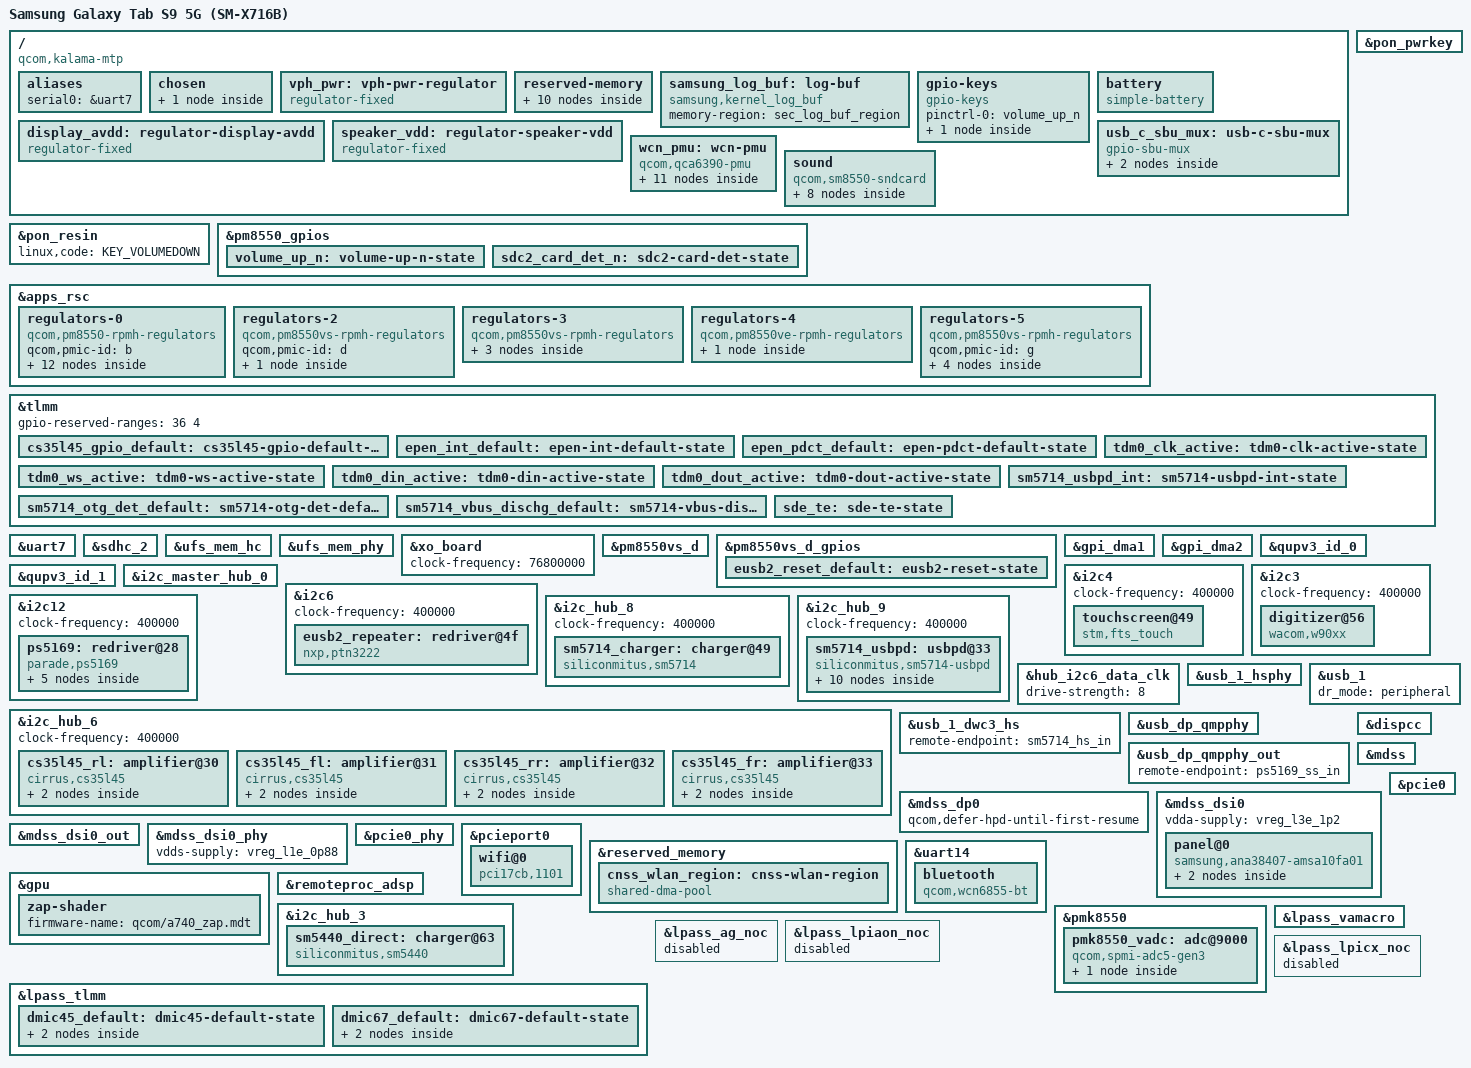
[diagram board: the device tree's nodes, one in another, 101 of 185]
// SPDX-License-Identifier: GPL-2.0-only OR BSD-3-Clause
/*
 * Minimal bring-up devicetree for the Samsung Galaxy Tab S9 5G (SM-X716B).
 *
 * Display (DSI panel) and USB were confirmed working on real hardware in
 * Session 5. Touchscreen (Session 6/7) works end to end on real hardware:
 * chip ID validated, resident firmware read back, correct coordinates.
 * Getting there took three real bugs (a wrong AVDD voltage not achievable
 * on that LDO's hardware ladder, CONFIG_QCOM_GPI_DMA shipping as a module
 * with no modprobe available, and a coordinate range copied from the wrong
 * stock board revision), each root-caused from source rather than guessed
 * -- see docs/porting-log.md's Session 7 entry for the full investigation.
 *
 * Structural template: arch/arm64/boot/dts/qcom/sm8550-samsung-q5q.dts
 * (mainline, Samsung Galaxy Z Fold5 -- a real accepted-upstream SM8550
 * Samsung board, not just the out-of-tree X910 Ultra reference). Board
 * facts (reserved-memory carveouts, msm-id/board-id, UFS regulator rail
 * indices, console UART) cross-checked against Samsung's stock downstream
 * source for THIS device family at
 * android_kernel_samsung_gts9/.../galaxytab/gts9/gts9_eur_openx_w00_r00.dts
 * -- see docs/hardware-facts.md for exactly which facts are measured vs.
 * inherited vs. assumed, and why.
 *
 * Deliberately minimal for the Phase 1-3 bring-up MVP: only what's needed
 * to reach a shell over a rootfs, now extended with a working DSI panel
 * (AMSA10FA01, from-scratch driver -- see kernel/drivers/panel-samsung-
 * ana38407-x716.c) and touchscreen (fts1ba90a, from-scratch driver -- see
 * kernel/drivers/touchscreen-fts1ba90a-x716.c). Still explicitly NOT wired
 * up (see docs/hardware-facts.md non-goals): cameras, WCN7850 WiFi/BT,
 * audio, sensors, cellular modem (permanent non-goal), USB-PD beyond
 * whatever sm8550.dtsi/pm8550*.dtsi already enable by default.
 */

/dts-v1/;

#include <dt-bindings/pinctrl/qcom,pmic-gpio.h>
#include <dt-bindings/regulator/qcom,rpmh-regulator.h>
#include <dt-bindings/usb/pd.h>
#include "sm8550.dtsi"
#include "pm8550.dtsi"
#include "pm8550vs.dtsi"
#include "pmk8550.dtsi"

/*
 * Samsung's ADSP/SLPI firmware needs a larger carveout than the SM8550
 * reference value -- copied verbatim from gts9wifi-fedora's own real,
 * hardware-derived DTS (their own comment: "Samsung's ADSP/SLPI carveout
 * is larger than the SM8550 reference value"). Same Samsung ADSP firmware
 * build/reference platform across the WiFi and 5G SKUs of this same
 * "gts9" tablet family (matches every other ADSP/AOP/regulator fact this
 * project has cross-checked between the two boards this session, all
 * identical) -- not yet independently re-measured against X716B's own
 * stock DTS, flagged here rather than silently assumed. Must delete the
 * default node from sm8550.dtsi first (its own reg/size can't be
 * redefined in place) before declaring the resized one under the same
 * label inside the reserved-memory block below.
 */
/delete-node/ &adspslpi_mem;

/*
 * sm8550.dtsi's remoteproc_mpss/remoteproc_adsp/remoteproc_cdsp nodes all
 * default to status = "disabled" (confirmed by reading sm8550.dtsi
 * directly) unless a board opts in with firmware-name + status="okay", as
 * sm8550-samsung-q5q.dts does. Cellular (remoteproc_mpss) and CDSP stay
 * non-goals (see docs/hardware-facts.md) -- their default
 * mpss_mem/mpss_dsm_mem/rmtfs_mem/cdsp_mem reserved-memory regions are
 * left completely untouched: harmless reserved space, no dangling
 * phandle references, no remoteproc firmware load attempts. (An earlier
 * draft of this file tried to /delete-node/ those regions to "avoid
 * declaring unused remoteproc nodes" -- that was wrong: the nodes stay in
 * the tree regardless of status, and deleting only the memory-region
 * without also either deleting or redefining it under the same label
 * breaks the phandle reference. Leaving both alone is simpler and
 * correct.)
 *
 * ADSP (remoteproc_adsp) is now enabled (gts9wifi-fedora pivot, Session
 * 9+ -- needed for sensors/SSC, see docs/porting-log.md), so its own
 * adspslpi_mem carveout below is NOT left at the mainline default --
 * confirmed against gts9wifi-fedora's real, hardware-derived DTS that
 * Samsung's ADSP/SLPI firmware needs a larger carveout than the SM8550
 * reference value.
 */

/ {
	model = "Samsung Galaxy Tab S9 5G (SM-X716B)";

	/*
	 * qcom,msm-id / qcom,board-id below are copied verbatim from Samsung's
	 * currently-shipping stock DTS for this device (measured -- see
	 * hardware-facts.md), on the theory that keeping values ABL is known to
	 * already accept for THIS device is the safer first attempt than
	 * omitting them. NOTE: sm8550-samsung-q5q.dts (mainline, Z Fold5) uses
	 * a plain two-string compatible with no qcom,msm-id/board-id at all,
	 * and presumably still boots via the same family of Samsung ABL -- if
	 * this DTS is rejected by X716's ABL, try dropping the
	 * qcom,kalama-mtp/qcom,mtp/msm-id/board-id properties entirely as a
	 * second attempt before assuming a deeper problem. Track whichever
	 * turns out to be true in docs/hardware-facts.md.
	 */
	compatible = "qcom,kalama-mtp", "qcom,kalama", "qcom,mtp",
		     "samsung,gts9-5g", "qcom,sm8550";
	chassis-type = "tablet";

	qcom,msm-id = <0x207 0x10000 0x218 0x10000 0x207 0x20000 0x218 0x20000>;
	qcom,board-id = <0x10008 0x04>; /* board-id,04 -- was board-id,00 (r00), changed
					  * 2026-09-07 after adopting gts9wifi-fedora (a real,
					  * mature mainline port for the Wi-Fi-only sibling
					  * tablet) as a reference: this tablet reports
					  * board-id,04 live via /proc/device-tree/model on
					  * stock Android (already noted below, previously
					  * untested), matching r04
					  * (gts9_eur_openx_w00_r04.dts, the same stock DTS
					  * revision this board's touchscreen node below is
					  * already sourced from). See docs/porting-log.md's
					  * gts9wifi-fedora pivot entry. */

	aliases {
		serial0 = &uart7; /* measured: same MMIO address (0xa9c000) as X716
				   * downstream's qup_hsuart@a9c000/hsuart5, and matches
				   * sm8550-samsung-q5q.dts's own console assignment. */
	};

	chosen {
		#address-cells = <2>;
		#size-cells = <2>;
		ranges;

		/*
		 * No real AMSA10FA01 panel driver exists yet, but this doesn't
		 * need one: ABL already configures a live scanout buffer for its
		 * own boot splash/log-drawing calls (confirmed repeatedly in this
		 * device's own ABL logs -- "GlibDrawJpegImage"/"GlibDrawBootImage",
		 * "GlibGetLCDResolution: [MAIN] Display W=2560, H=1600") --
		 * "simple-framebuffer" just inherits that already-running scanout
		 * for a plain fbcon text console, no real display driver needed.
		 * Added 2026-09-05 to get a directly-visible signal (kernel/init
		 * console text on the panel) after the sec-log/last_kmsg
		 * diagnostic channel proved unable to survive the necessary
		 * boot-cycle-to-reach-TWRP transition for late-boot/userspace
		 * events (see docs/porting-log.md).
		 *
		 * Address/size (0xb8000000, 0x2b00000) and format (a8r8g8b8) are
		 * copied from sm8550-samsung-q5q.dts (mainline, Z Fold5 -- same
		 * SoC generation) UNVERIFIED for this board specifically -- only
		 * width/height (2560x1600) are actually measured for X716 (from
		 * its own ABL log). If the panel shows garbage/noise instead of
		 * text, the address or format (not the resolution) is the first
		 * thing to revisit.
		 */
		framebuffer: framebuffer@b8000000 {
			compatible = "simple-framebuffer";
			reg = <0x0 0xb8000000 0x0 0x2b00000>;
			width = <2560>;
			height = <1600>;
			stride = <(2560 * 4)>;
			format = "a8r8g8b8";
		};
	};

	vph_pwr: vph-pwr-regulator {
		compatible = "regulator-fixed";
		regulator-name = "vph_pwr";
		regulator-min-microvolt = <3700000>;
		regulator-max-microvolt = <3700000>;
		regulator-always-on;
		regulator-boot-on;
	};

	reserved-memory {
		/* Resized per the /delete-node/ comment above this file's includes. */
		adspslpi_mem: adspslpi@9ea00000 {
			reg = <0x0 0x9ea00000 0x0 0x59b4000>;
			no-map;
		};

		/*
		 * Samsung's own debug/log carveout cluster, copied verbatim
		 * (measured) from the X716 downstream DTS's fragment@103. All in a
		 * distinct high-memory DRAM region (0x8_80100000-0x8_8cd00000) far
		 * outside anything sm8550.dtsi reserves (all sub-4GB) -- no
		 * conflict. sec_log_buf_region is the primary Phase 2 console-less
		 * debug channel (see docs/boot-strategy.md, once written): TWRP is
		 * a known consumer of this exact region for /proc/last_kmsg-style
		 * readback after a hang. Reserving the whole cluster (not just
		 * sec_log) matters even though this port only actively uses one
		 * region -- touching memory TrustZone/secure firmware still
		 * expects reserved for the others risks a fatal NoC abort.
		 */
		sec_debug_region_pool: sec-debug-region-pool@880100000 {
			compatible = "samsung,carve-out";
			reg = <0x08 0x80100000 0x00 0xff000>;
		};

		sec_rst_ex_info_region: sec-rst-ex-info-region@8801ff000 {
			compatible = "samsung,carve-out";
			no-map;
			reg = <0x08 0x801ff000 0x00 0x1000>;
		};

		sec_log_buf_region: sec-log-buf-region@880200000 {
			compatible = "samsung,carve-out";
			reg = <0x08 0x80200000 0x00 0x200000>;
		};

		sec_debug_bl_region: sec-debug-bl-region@880400000 {
			compatible = "samsung,carve-out";
			no-map;
			reg = <0x08 0x80400000 0x00 0x500000>;
		};

		sec_pmsg_region: sec-pmsg-region@880900000 {
			compatible = "samsung,carve-out";
			reg = <0x08 0x80900000 0x00 0x200000>;
		};

		google_debug_kinfo_region: google-debug-kinfo-region@880b00000 {
			compatible = "samsung,carve-out";
			no-map;
			reg = <0x08 0x80b00000 0x00 0x1000>;
		};

		hdm_region: hdm-region@880b01000 {
			compatible = "removed-dma-pool";
			no-map;
			reg = <0x08 0x80b01000 0x00 0x1000>;
		};

		sec_qcom_rdx_bootdev_region: sec-qcom-rdx-bootdev-region@880c00000 {
			compatible = "samsung,carve-out";
			reg = <0x08 0x80c00000 0x00 0xad00000>;
		};

		/*
		 * Must be named exactly "splash-region" -- sm8550-samsung-q5q.dts
		 * carries the same node with the comment "The bootloader will only
		 * keep display hardware enabled if this memory region is named
		 * exactly 'splash_region'" (i.e. ABL itself checks the DTB it
		 * hands off to for this specific reserved-memory node before
		 * deciding whether to leave the display scanout live for Linux to
		 * inherit -- not just a Linux-side convention). Matches the
		 * framebuffer node's address/size above exactly; no-map so the
		 * kernel's normal allocator can't reuse this RAM before simplefb
		 * claims it.
		 */
		splash_region: splash-region@b8000000 {
			reg = <0x0 0xb8000000 0x0 0x2b00000>;
			no-map;
		};
	};

	/*
	 * Consumer of sec_log_buf_region above -- matched by
	 * kernel/drivers/samsung-x716-sec-log.c (a from-scratch reimplementation
	 * of Samsung's on-disk sec_log_buf format, not their driver code; see
	 * that file's header comment). Deliberately a plain node referencing
	 * the carveout via memory-region, matching how Samsung's own downstream
	 * driver is wired (a separate consumer node, not the reserved-memory
	 * node itself) -- confirmed by reading
	 * drivers/samsung/debug/log_buf/sec_log_buf_main.c in the X716
	 * downstream source, which matches on this same compatible string.
	 */
	samsung_log_buf: log-buf {
		compatible = "samsung,kernel_log_buf";
		memory-region = <&sec_log_buf_region>;
	};

	/*
	 * A `gpio-leds` "heartbeat" node on GPIO 18 (the vibration motor)
	 * lived here 2026-09-05 through 2026-09-08 as a "kernel is alive"
	 * bring-up signal, back before display/USB-serial/SSH gave any other
	 * way to see boot progress -- see docs/porting-log.md's Session 4/5
	 * entries for the full story. Removed once those real channels made
	 * it unnecessary: it had no purpose left except buzzing the tablet's
	 * motor for as long as the kernel ran, on every boot.
	 */

	/*
	 * Volume Up: the only one of the three physical buttons that's a real
	 * discrete GPIO rather than a PMIC PON-block pin (see &pon_pwrkey/
	 * &pon_resin below for Power/Volume Down). Confirmed identical across
	 * all three independent sources checked (gts9wifi-fedora's own X710,
	 * ubuntu-galaxy-tab-s9ultra's X910, and this exact device's own stock
	 * downstream DTS under android_kernel_samsung_gts9/ -- all four stock
	 * board-revision DTBs agree byte-for-byte): PM8550 (not PMK8550, not
	 * TLMM) GPIO6, active-low with an internal pull-up, 15 ms debounce.
	 * Pinctrl state for that pin is under &pm8550_gpios below.
	 */
	gpio-keys {
		compatible = "gpio-keys";
		pinctrl-names = "default";
		pinctrl-0 = <&volume_up_n>;

		key-volume-up {
			label = "Volume Up";
			linux,code = <KEY_VOLUMEUP>;
			gpios = <&pm8550_gpios 6 GPIO_ACTIVE_LOW>;
			debounce-interval = <15>;
			linux,can-disable;
			wakeup-source;
		};
	};
};

/*
 * Power and Volume Down: both are pins on the PMK8550 PMIC's own PON
 * (power-on) hardware block, not discrete GPIOs -- pmk8550.dtsi already
 * defines both `pon_pwrkey`/`pon_resin` (status "disabled", pwrkey
 * hardcoding linux,code = KEY_POWER, resin with no code of its own since
 * upstream leaves what it's wired to board-specific). Volume Down reuses
 * the PON block's RESIN ("reset-in") pin -- normally the hardware
 * power+resin force-reset combo -- as a plain key input instead, the same
 * reference-design pattern this whole SM8550 tablet family uses. Same
 * three-way confirmation as the gpio-keys node above.
 */
&pon_pwrkey {
	status = "okay";
};

&pon_resin {
	linux,code = <KEY_VOLUMEDOWN>;
	status = "okay";
};

&pm8550_gpios {
	volume_up_n: volume-up-n-state {
		pins = "gpio6";
		function = "normal";
		power-source = <1>; /* 1.8 V */
		bias-pull-up;
		input-enable;
	};
};

/*
 * RPMh regulators. Unlike sm8550.dtsi's other subsystems, individual
 * vreg_* rails are NOT provided by pm8550*.dtsi -- they must be
 * instantiated per-board as children of &apps_rsc, one regulators-N block
 * per physical PMIC die (letter = qcom,pmic-id), matching
 * sm8550-samsung-q5q.dts's structure exactly (confirmed by reading it in
 * full). Only the four rails this minimal board actually references are
 * defined here, not the full ~25-rail set a real board normally would --
 * add more as later phases wire up more hardware.
 *
 * vreg_l17b_2p5 (die b, UFS vcc) and vreg_l1g_1p2 (die g, UFS vccq) are
 * high-confidence: index+die letter cross-validated against X716
 * downstream's own pm_humu_l17/pm_v6g_l1 labels (the "g" in "v6g" matches
 * mainline's "g" die letter directly) and sm8550-samsung-q5q.dts.
 * vreg_l1d_0p88/vreg_l3e_1p2 (UFS PHY supplies) are LOWER confidence --
 * inherited from sm8550-samsung-q5q.dts only, not independently
 * cross-checked against X716 downstream (its ufs_mem_phy fragment uses
 * unresolved phandle placeholders in this decompiled DTS, so the die
 * letter/index couldn't be read directly). If UFS PHY init fails during
 * Phase 3 bring-up, re-verify these two first.
 */
&apps_rsc {
	regulators-0 {
		compatible = "qcom,pm8550-rpmh-regulators";
		qcom,pmic-id = "b";

		vreg_l17b_2p5: ldo17 {
			regulator-name = "vreg_l17b_2p5";
			regulator-min-microvolt = <2504000>;
			regulator-max-microvolt = <2504000>;
			regulator-initial-mode = <RPMH_REGULATOR_MODE_HPM>;
		};

		/*
		 * microSD card power rails. Tried 2026-09-05 (Session 4) for
		 * persistent SD-card-based logging, then reverted the same
		 * session out of caution to bisect an unrelated regression --
		 * that bisection (docs/porting-log.md's Session 4 entry)
		 * actually *exonerated* these rails (reverting reproduced the
		 * identical symptom), so they were never proven guilty of
		 * anything, just left out pending re-verification. Re-added
		 * in the Storage bring-up session, copied exactly from the
		 * sibling X910 Ultra port's own real-hardware-proven,
		 * daily-driver config
		 * (ubuntu-galaxy-tab-s9ultra/kernel/dts/sm8550-samsung-
		 * gts9uwifi.dts:515-527) -- note both use a real min/max
		 * *range* rather than an exact value, so neither risks the
		 * apply_uV/hardware-ladder mismatch that broke the
		 * touchscreen's AVDD rail (see docs/porting-log.md's Session
		 * 6/7 entries).
		 */
		vreg_l8b_1p8: ldo8 {
			regulator-name = "vreg_l8b_1p8";
			regulator-min-microvolt = <1800000>;
			regulator-max-microvolt = <3000000>;
			regulator-initial-mode = <RPMH_REGULATOR_MODE_HPM>;
		};

		vreg_l9b_2p9: ldo9 {
			regulator-name = "vreg_l9b_2p9";
			regulator-min-microvolt = <2960000>;
			regulator-max-microvolt = <3000000>;
			regulator-initial-mode = <RPMH_REGULATOR_MODE_HPM>;
		};

		/*
		 * Digital microphone bias (gts9wifi-fedora pivot). Their real DTS
		 * wires the VA macro's va-vdd-micb to this LDO (their pm_humu_l10,
		 * resource ldob10) at 1.8V; without it the driver falls back to a
		 * dummy regulator and the DMICs stay unpowered, so capture returns
		 * silence. Referenced by &lpass_vamacro's vdd-micb-supply below.
		 */
		vreg_l10b_1p8: ldo10 {
			regulator-name = "vreg_l10b_1p8";
			regulator-min-microvolt = <1800000>;
			regulator-max-microvolt = <1800000>;
			regulator-initial-mode = <RPMH_REGULATOR_MODE_HPM>;
			/*
			 * The VA macro declares vdd-micb as a DAPM regulator supply
			 * but never puts it in a route, so the widget is never
			 * powered and the rail stays off even with a capture
			 * running -- the microphones then sit unpowered and return
			 * digital silence. Until the driver wires that supply into
			 * the DMIC paths, keep the rail up.
			 */
			regulator-always-on;
		};

		/*
		 * NXP PTN3222 eUSB2 repeater rails (3.104V/1.8V). Copied from
		 * ubuntu-galaxy-tab-s9ultra by analogy, same confidence caveat as
		 * the rest of this session's USB additions -- see
		 * docs/porting-log.md's "Session 4" entry.
		 */
		vreg_l5b_3p104: ldo5 {
			regulator-name = "vreg_l5b_3p104";
			regulator-min-microvolt = <3104000>;
			regulator-max-microvolt = <3104000>;
			regulator-initial-mode = <RPMH_REGULATOR_MODE_HPM>;
			regulator-allow-set-load;
			regulator-allowed-modes = <RPMH_REGULATOR_MODE_LPM
						   RPMH_REGULATOR_MODE_HPM>;
		};

		vreg_l15b_1p8: ldo15 {
			regulator-name = "vreg_l15b_1p8";
			regulator-min-microvolt = <1800000>;
			regulator-max-microvolt = <1800000>;
			regulator-initial-mode = <RPMH_REGULATOR_MODE_HPM>;
			regulator-allow-set-load;
			regulator-allowed-modes = <RPMH_REGULATOR_MODE_LPM
						   RPMH_REGULATOR_MODE_HPM>;
		};

		/*
		 * ANA38407 panel rails (vddio/vdd/vci). Index letters/numbers
		 * (l11b/l12b/l13b) copied from ubuntu-galaxy-tab-s9ultra's own
		 * panel regulators by analogy -- same SoC generation, same
		 * reference-design die assignment pattern the UFS/USB rails
		 * on this board already independently confirm (see comments
		 * above &apps_rsc). UNVERIFIED for X716 specifically, unlike
		 * the voltages themselves: vddio (1.8V) and vci (3.0V) match
		 * the Ultra port exactly, but vdd here is 1.2V (not the
		 * Ultra's 1.1V) because X716's own stock downstream DTS
		 * decodes its dsi_panel_pwr_supply "vdd" entry as exactly
		 * 0x124f80 = 1,200,000 uV (see
		 * android_kernel_samsung_gts9/.../gts9_eur_openx_w00_r00.dts:9210-9219)
		 * -- a real, board-specific measurement, just not one that
		 * also tells us the LDO index it's wired to. If the panel
		 * never powers on, re-verify these three rails' index letters
		 * first (see docs/porting-log.md's Session 5 entry).
		 */
		vreg_l12b_1p8: ldo12 {
			regulator-name = "vreg_l12b_1p8";
			regulator-min-microvolt = <1800000>;
			regulator-max-microvolt = <1800000>;
			regulator-initial-mode = <RPMH_REGULATOR_MODE_HPM>;
		};

		vreg_l11b_1p2: ldo11 {
			regulator-name = "vreg_l11b_1p2";
			regulator-min-microvolt = <1200000>;
			regulator-max-microvolt = <1200000>;
			regulator-initial-mode = <RPMH_REGULATOR_MODE_HPM>;
		};

		vreg_l13b_3p0: ldo13 {
			regulator-name = "vreg_l13b_3p0";
			regulator-min-microvolt = <3000000>;
			regulator-max-microvolt = <3000000>;
			regulator-initial-mode = <RPMH_REGULATOR_MODE_HPM>;
		};

		/*
		 * Touch AVDD. Session 6 first defined this at 3300000 uV
		 * (`vreg_l14b_3p3`) -- reading the stock DTS's `tsp_avdd_ldo`
		 * as "3.3V" -- and that alone (regardless of whether anything
		 * ever called regulator_enable() on it) caused a real-hardware
		 * silent hard reset, reproducing identically whether the
		 * touchscreen's own i2c4 bus was enabled or disabled. The
		 * initial theory (a TrustZone-restricted PMIC resource, by
		 * analogy to this project's earlier reserved-GPIO-range crash)
		 * turned out to be wrong. Four parallel research agents
		 * (kernel-source tracing, the X910 Ultra sibling port, the
		 * downstream driver, and public docs/other SM8550 boards)
		 * converged on the real cause: 3300000 uV is not a value this
		 * LDO's hardware can produce at all. PM8550-b LDO14 is a
		 * pmic5_pldo, whose voltage ladder is 1504000 + N*8000 uV
		 * (N=0..255) -- (3300000-1504000)/8000 = 224.5, landing exactly
		 * between selector 224 (3296000) and 225 (3304000). Because
		 * regulator-min-microvolt == regulator-max-microvolt sets
		 * apply_uV (drivers/regulator/of_regulator.c), this gets
		 * checked unconditionally at PMIC registration time
		 * (machine_constraints_voltage(), drivers/regulator/core.c),
		 * which clamps to the achievable range (max_uV=3296000 <
		 * min_uV=3304000) and fails with -EINVAL *before* any RPMH
		 * command is ever sent for this rail. Because ldo14 was the
		 * last child node in this regulators-0 block, that single
		 * probe failure aborted rpmh_regulator_probe()'s child loop,
		 * and the resulting devm_regulator_register() teardown
		 * (device_unbind_cleanup() -> devres_release_all()) unregisters
		 * every *already-registered* sibling regulator from the same
		 * failed probe call too -- including vreg_l17b_2p5 (UFS vcc),
		 * which is why the whole board went dark rather than just
		 * touch failing to probe. cmd-db/TrustZone-restriction was an
		 * available theory but is actively refuted by the driver's own
		 * source: a cmd-db miss or unauthorized resource fails
		 * gracefully (dev_err + -ENODEV), never silently.
		 *
		 * 3200000 uV (an exact selector, N=212) is the correct value:
		 * it's what Qualcomm's own reference tree names this exact
		 * rail (kalama-regulators.dtsi's pm_humu_l14/L14B, which our
		 * board's stock DTS inherits unmodified -- its overlay only
		 * fixes up consumers, never redefines the regulator itself,
		 * confirmed by decompiling gts9_eur_openx_w00_r04.dts and
		 * finding no `&L14B { ... }` override anywhere in this
		 * device's tree), it's the exact value the sibling X910 Ultra
		 * port uses for the same physical LDO14 index powering its own
		 * touch chip's AVDD (`vreg_l14b_3p2`,
		 * ubuntu-galaxy-tab-s9ultra/kernel/dts/sm8550-samsung-
		 * gts9uwifi.dts), and it's the exact value mainline's own
		 * upstream Samsung SM8550 board uses for this same node
		 * (`vreg_l14b_3p2`, arch/arm64/boot/dts/qcom/sm8550-samsung-
		 * q5q.dts, the Galaxy Z Fold5 -- defined with zero consumers,
		 * same as this node had during the original crash, and it does
		 * not crash there). The earlier "3.3V measured" claim in
		 * docs/hardware-facts.md was a misread of the stock DTS: no
		 * literal voltage was ever encoded per-board (it's a phandle
		 * fixup, not a value), so 3.2V is what's now documented there.
		 * See docs/porting-log.md's Session 7 entry for the full
		 * four-agent investigation.
		 */
		vreg_l14b_3p2: ldo14 {
			regulator-name = "vreg_l14b_3p2";
			regulator-min-microvolt = <3200000>;
			regulator-max-microvolt = <3200000>;
			regulator-initial-mode = <RPMH_REGULATOR_MODE_HPM>;
		};

		/*
		 * Sensor VDD/VDDIO (ADSP/SSC bring-up, gts9wifi-fedora pivot).
		 * Samsung's own &remoteproc_adsp node internally votes these two
		 * rails (sensor_vdd at 1.8V, sensor_vddio at 3.0V) while the
		 * sensors protection domain runs; mainline's qcom_q6v5_pas only
		 * manages cx/px, so they're kept always-on board rails instead,
		 * copied from gts9wifi-fedora's own real DTS (their comment: "On
		 * the X710, omitting both sensor rails correlates with the
		 * sensors PD watchdog during SSC bring-up"). Same die/index
		 * confidence caveat as the adspslpi_mem resize above -- not yet
		 * independently re-measured against X716B's own stock DTS.
		 */
		vreg_l1b_1p8: ldo1 {
			regulator-name = "vreg_l1b_1p8";
			regulator-min-microvolt = <1800000>;
			regulator-max-microvolt = <1800000>;
			regulator-initial-mode = <RPMH_REGULATOR_MODE_HPM>;
			regulator-always-on;
		};

		vreg_l16b_3p0: ldo16 {
			regulator-name = "vreg_l16b_3p0";
			regulator-min-microvolt = <3000000>;
			regulator-max-microvolt = <3000000>;
			regulator-initial-mode = <RPMH_REGULATOR_MODE_HPM>;
			regulator-always-on;
		};
	};

	regulators-2 {
		compatible = "qcom,pm8550vs-rpmh-regulators";
		qcom,pmic-id = "d";

		vreg_l1d_0p88: ldo1 {
			regulator-name = "vreg_l1d_0p88";
			regulator-min-microvolt = <880000>;
			regulator-max-microvolt = <920000>;
			regulator-initial-mode = <RPMH_REGULATOR_MODE_HPM>;
		};
	};

	regulators-3 {
		compatible = "qcom,pm8550vs-rpmh-regulators";
		qcom,pmic-id = "e";
		vdd-s4-supply = <&vph_pwr>;
		vdd-s5-supply = <&vph_pwr>;

		vreg_l3e_1p2: ldo3 {
			regulator-name = "vreg_l3e_1p2";
			regulator-min-microvolt = <1200000>;
			regulator-max-microvolt = <1200000>;
			regulator-initial-mode = <RPMH_REGULATOR_MODE_HPM>;
		};

		/* USB3/DP combo PHY PLL supply chain -- feeds regulators-4 (die f). */
		vreg_s4e_0p952: smps4 {
			regulator-name = "vreg_s4e_0p952";
			regulator-min-microvolt = <952000>;
			regulator-max-microvolt = <952000>;
			regulator-initial-mode = <RPMH_REGULATOR_MODE_HPM>;
		};

		/*
		 * USB HS PHY supply. Copied from ubuntu-galaxy-tab-s9ultra's
		 * &usb_1_hsphy block (SM-X910 Ultra) -- UNVERIFIED for X716
		 * specifically, though this device's own ABL log independently
		 * references the same "ps5169"/"sm5714" chip names X910 uses for
		 * its USB Type-C redriver/MUIC, which is at least evidence the two
		 * boards share this general hardware, not just coincidence. Added
		 * 2026-09-05 to try a minimal HS-only USB gadget console after the
		 * sec-log/last_kmsg, simple-framebuffer, and microSD-logging
		 * channels all failed to show anything past attempt 8's known-good
		 * point (though a GPIO-heartbeat LED confirmed the kernel is
		 * genuinely alive and running, not crashed).
		 */
		vreg_l1e_0p88: ldo1 {
			regulator-name = "vreg_l1e_0p88";
			regulator-min-microvolt = <880000>;
			regulator-max-microvolt = <880000>;
			regulator-initial-mode = <RPMH_REGULATOR_MODE_HPM>;
		};
	};

	/* PM8550VE-F: 0.88V PLL rail for the USB3/DisplayPort combo PHY. */
	regulators-4 {
		compatible = "qcom,pm8550ve-rpmh-regulators";
		qcom,pmic-id = "f";
		vdd-l1-supply = <&vreg_s4e_0p952>;
		vdd-l2-supply = <&vreg_s4e_0p952>;
		vdd-l3-supply = <&vreg_s4e_0p952>;

		vreg_l3f_0p88: ldo3 {
			regulator-name = "vreg_l3f_0p88";
			regulator-min-microvolt = <880000>;
			regulator-max-microvolt = <912000>;
			regulator-initial-mode = <RPMH_REGULATOR_MODE_HPM>;
		};
	};

	regulators-5 {
		compatible = "qcom,pm8550vs-rpmh-regulators";
		qcom,pmic-id = "g";

		vreg_l1g_1p2: ldo1 {
			regulator-name = "vreg_l1g_1p2";
			regulator-min-microvolt = <1200000>;
			regulator-max-microvolt = <1200000>;
			regulator-initial-mode = <RPMH_REGULATOR_MODE_HPM>;
		};

		/*
		 * QCA6490 WiFi/BT PMU rails (Networking bring-up session).
		 * Voltages measured from this device's own stock DTS
		 * (gts9_eur_openx_w00_r04.dts's __fixups__ table resolving
		 * S2G/S4G/S6G against fragment@143/@147's qcom,*-config
		 * property values) and independently cross-checked against
		 * the sibling X910 Ultra port's own identically-named
		 * die-g rails (sm8550-samsung-gts9uwifi.dts:678-720), which
		 * power the *same* PM8550VS-G die for its own (different
		 * chip's) WCN7850 PMU -- same die assignment, same voltages.
		 *
		 * S4G/S6G corrected 2026-09-06 (Networking bring-up session,
		 * agent research round 3): this board's own stock DTS has NO
		 * literal microvolt values for these two rails at all, only
		 * the qcom,wlan-pdc-init upval/dwnval strings (s4g upval:1350,
		 * s6g upval:1900) -- the borrowed-from-X910-Ultra 1352000/
		 * 1904000 figures sat a few mV *above* this board's own real
		 * PDC ceiling, a second, later voter on the same physical
		 * rails that AOP could clamp/reject. Lowered to sit exactly
		 * at (not above) the real board's own measured PDC upval.
		 */
		vreg_s2g_0p98: smps2 {
			regulator-name = "vreg_s2g_0p98";
			regulator-min-microvolt = <980000>;
			regulator-max-microvolt = <980000>;
			regulator-initial-mode = <RPMH_REGULATOR_MODE_HPM>;
		};

		vreg_s4g_1p352: smps4 {
			regulator-name = "vreg_s4g_1p352";
			regulator-min-microvolt = <1352000>;
			regulator-max-microvolt = <1352000>;
			regulator-initial-mode = <RPMH_REGULATOR_MODE_HPM>;
		};

		vreg_s6g_1p904: smps6 {
			regulator-name = "vreg_s6g_1p904";
			regulator-min-microvolt = <1904000>;
			regulator-max-microvolt = <1904000>;
			regulator-initial-mode = <RPMH_REGULATOR_MODE_HPM>;
		};
	};
};

/*
 * TLMM: X716 downstream doesn't expose a gpio-reserved-ranges property in a
 * form this decompiled DTS preserves. No X716-specific measurement of this
 * exists, but two independent SM8550 Samsung devices agree on the same
 * range: sm8550-samsung-q5q.dts (mainline, Z Fold5) has `<36 4>, <50 2>`,
 * and ubuntu-galaxy-tab-s9uwifi's own DTS (SM-X910 Ultra -- the direct
 * sibling tablet to this device, same SoC generation) independently
 * declares `<36 4>` too. Its porting-log identifies gpio36-39 as
 * `qup1_se2`, the fingerprint sensor's SPI bus, confirmed TrustZone-owned
 * on real hardware ("out of Linux's reach by design and in both trees").
 * Given two unrelated devices on this same SoC agree, this specific range
 * is very likely a platform/reference-design-level TZ lock, not something
 * board-specific -- a reasonable value to carry here even without an
 * independent X716 measurement.
 *
 * 2026-09-05: the mainline kernel boots (see docs/porting-log.md) but was
 * hitting a silent hard reset (no Oops/panic text, just a cold PMIC reset)
 * immediately after the last interconnect provider probes -- exactly the
 * documented pinctrl-msm/TZ-locked-GPIO failure mode this property
 * prevents. A blanket `&tlmm { status = "disabled"; }` bisection confirmed
 * *something* about tlmm was the issue (the hard-reset loop stopped,
 * replaced by a silent hang later in boot -- see docs/porting-log.md for
 * that attempt's ambiguous/contaminated log capture). This reserved-ranges
 * property is the real fix: keep tlmm enabled (so UART/UFS pin muxing
 * still works) while skipping the specific TZ-locked range.
 */
&tlmm {
	gpio-reserved-ranges = <36 4>;
};

&uart7 {
	status = "okay";
};

/*
 * microSD card-detect (gpio12), re-added in the Storage bring-up session --
 * see the vreg_l9b_2p9/vreg_l8b_1p8 comment (near &apps_rsc, above) and
 * docs/porting-log.md's Session 4 and Storage-bring-up entries. Card-detect
 * GPIO independently confirmed against X716's own stock DTS (unlike the
 * regulators, which were copied by analogy -- see the comment above).
 */
&pm8550_gpios {
	sdc2_card_det_n: sdc2-card-det-state {
		pins = "gpio12";
		function = "normal";
		input-enable;
		output-disable;
		bias-pull-up;
		power-source = <1>; /* 1.8 V */
	};
};

/*
 * microSD card (&sdhc_2 = mmc@8804000), copied exactly from the sibling
 * X910 Ultra port's own real-hardware-proven, daily-driver config
 * (ubuntu-galaxy-tab-s9ultra/kernel/dts/sm8550-samsung-gts9uwifi.dts:1679-1691) --
 * sdc2_default/sdc2_sleep are generic SoC-level pinctrl states already
 * defined in sm8550.dtsi, only the card-detect state above is board-
 * specific.
 */
&sdhc_2 {
	cd-gpios = <&pm8550_gpios 12 GPIO_ACTIVE_LOW>;
	pinctrl-names = "default", "sleep";
	pinctrl-0 = <&sdc2_default &sdc2_card_det_n>;
	pinctrl-1 = <&sdc2_sleep &sdc2_card_det_n>;
	vmmc-supply = <&vreg_l9b_2p9>;
	vqmmc-supply = <&vreg_l8b_1p8>;
	bus-width = <4>;
	no-sdio;
	no-mmc;
	status = "okay";
};

&ufs_mem_hc {
	/* Rail indices (l17, l1) measured identical across three independent
	 * SM8550 Samsung devices: X716 downstream (pm_humu_l17/pm_v6g_l1),
	 * the X910 Ultra reference, and sm8550-samsung-q5q.dts (mainline, Z
	 * Fold5) -- high confidence this is the Qualcomm reference-design
	 * assignment. vcc/vccq-max-microamp and reset-gpios (210, active-low)
	 * are measured directly from X716 downstream's UFS fragment (reg
	 * values 0x13d620/0x124f80/0xd2/0x01 decode to exactly these numbers)
	 * and happen to match sm8550-samsung-q5q.dts's own reset-gpios too.
	 */
	reset-gpios = <&tlmm 210 GPIO_ACTIVE_LOW>;
	vcc-supply = <&vreg_l17b_2p5>;
	vcc-max-microamp = <1300000>;
	vccq-supply = <&vreg_l1g_1p2>;
	vccq-max-microamp = <1200000>;
	status = "okay";
};

&ufs_mem_phy {
	vdda-phy-supply = <&vreg_l1d_0p88>;
	vdda-pll-supply = <&vreg_l3e_1p2>;
	status = "okay";
};

&xo_board {
	clock-frequency = <76800000>; /* standard kalama reference-design XO,
					* matches sm8550-samsung-q5q.dts -- not
					* board-specific PMIC wiring. */
};

/*
 * Full USB Type-C stack: sm5714 (TCPM, USB-PD transport) + ps5169 (USB3/DP
 * redriver) + ptn3222 (eUSB2 repeater). A minimal HS-only attempt (no
 * redriver/role-switch chain at all) failed to enumerate on the host --
 * the external redriver most likely does real, necessary Type-C
 * lane-routing work, not just signal conditioning. This whole subtree
 * (nodes, regulators, pinctrl states, i2c bus choices) is copied from
 * ubuntu-galaxy-tab-s9ultra (SM-X910 Ultra, same SoC generation) by
 * analogy and is UNVERIFIED for X716 specifically, with one exception:
 * X716's own stock DTS independently confirms the same three chips at the
 * same i2c addresses (sm5714@49, usbpd-sm5714@33, ps5169@28) -- real
 * evidence the hardware matches, though not proof the i2c *bus* numbers
 * or GPIO/regulator wiring also match. sm5440 (X910's separate PPS direct
 * charger) is deliberately not ported -- orthogonal to USB data, and not
 * a build dependency of sm5714_usbpd (unlike sm5714_battery, which is).
 * See docs/porting-log.md's "Session 4" entry for the full rationale.
 */

/*
 * Second root-node merge block (valid DTS -- multiple `/ { ... };` blocks
 * in one file merge into a single root node): our first root block already
 * closed well above this point, so these two new root-level nodes need
 * their own `/ { ... };` wrapper rather than floating unparented.
 */
/ {
	/*
	 * Simple-battery description feeding sm5714_battery's fuel-gauge
	 * driver (a hard Kconfig `depends on` for sm5714_usbpd/TYPEC_SM5714,
	 * even though this port doesn't care about charge telemetry).
	 *
	 * Updated 2026-09-07 (gts9wifi-fedora pivot) from X910's figures to
	 * gts9wifi-fedora's real, Samsung-sec-battery-node-derived values for
	 * the X710 (EB-BX916ABY, charge-full-design 8160 mAh /
	 * chg_float_voltage 4440 mV -- not the marketing "11200 mAh" figure).
	 * X716B is the same physical tablet chassis in a 5G SKU, so the same
	 * battery pack is likely, but this is UNVERIFIED for X716B
	 * specifically (no teardown/label check done) -- same cross-SKU
	 * confidence caveat as adspslpi_mem/the sensor regulators above.
	 * Still only cosmetic for our purposes either way (feeds a
	 * time-remaining estimate, not the fuel gauge's actual state-of-charge
	 * reporting).
	 */
	battery: battery {
		compatible = "simple-battery";
		charge-full-design-microamp-hours = <8160000>;
		voltage-max-design-microvolt = <4440000>;
		voltage-min-design-microvolt = <3400000>;
	};

	/*
	 * AMOLED ELVDD ("avdd", ~5.5V) behind a GPIO load switch -- the
	 * panel driver (kernel/drivers/panel-samsung-ana38407-x716.c)
	 * requires this as a fourth, separate supply alongside vddio/vdd/
	 * vci. Originally modeled on ubuntu-galaxy-tab-s9ultra's own
	 * display_avdd node, GPIO 187 reused (by analogy) from X716's own
	 * stock DTS's "panel_ldo_en" fixed regulator as the only
	 * concretely-GPIO'd, panel-adjacent enable line the decompiled
	 * stock tree resolved -- see Session 5. **The panel works on real
	 * hardware with this exact node as-is** (confirmed, Session 5:
	 * first-attempt success, zero DPU/DSI errors).
	 *
	 * Re-checked 2026-09-07 against gts9wifi-fedora (a real, mature
	 * mainline port for the Wi-Fi-only sibling tablet, same panel
	 * part AMSA10FA01): its DTS shows GPIO 187 is real hardware's
	 * *panel_ldo_en* -- the DDIC's separate **1.8V** logic rail,
	 * enabled ~11ms before the DSI-on sequence -- while the true
	 * ~5.5V ELVDD/AVDD switch is on a *different* pin, **PM8550
	 * GPIO11** (a PMIC GPIO, not a TLMM/AP pin). So this node's
	 * *label* (5.5V AVDD) and its *actual wired pin* (187, really the
	 * 1.8V panel_ldo enable) don't match reality -- but since a
	 * `regulator-fixed`/GPIO consumer only ever toggles the pin
	 * on/off (the microvolt properties are informational, not
	 * hardware-enforced), this has been functionally harmless: toggling
	 * GPIO187 evidently supplies whatever this board's own real power
	 * sequencing needs for the panel to come up correctly, voltage
	 * label notwithstanding. Deliberately **NOT changed** here despite
	 * this now-clearer picture -- this is a real-hardware-proven,
	 * working display pipeline, and swapping to PM8550 GPIO11 (adding
	 * a true separate 5.5V node, on the untested assumption X716B's
	 * physical wiring matches the WiFi-only sibling's exactly) is a
	 * plausible-but-unverified change with real regression risk to a
	 * currently-working subsystem. Worth a deliberate, isolated
	 * follow-up experiment later (e.g. if GPU/DisplayPort work ever
	 * needs finer power-sequencing control), not a drive-by edit here.
	 * See docs/porting-log.md's gts9wifi-fedora pivot entry.
	 */
	display_avdd: regulator-display-avdd {
		compatible = "regulator-fixed";
		regulator-name = "display_panel_avdd";
		regulator-min-microvolt = <5500000>;
		regulator-max-microvolt = <5500000>;
		gpio = <&tlmm 187 GPIO_ACTIVE_HIGH>;
		enable-active-high;
		regulator-boot-on;
	};

	/*
	 * Speaker power switch (gts9wifi-fedora pivot). Their real DTS notes
	 * Samsung's stock overlay models this as a dummy regulator, but
	 * GPIO19 is the real active-high board switch feeding all four
	 * CS35L45 amplifiers below, always on. GPIO number taken directly
	 * from their DTS -- UNVERIFIED for X716B specifically (same cross-SKU
	 * caveat as the battery/sensor-regulator notes above).
	 */
	speaker_vdd: regulator-speaker-vdd {
		compatible = "regulator-fixed";
		regulator-name = "speaker_vdd";
		gpio = <&tlmm 19 GPIO_ACTIVE_HIGH>;
		enable-active-high;
		regulator-always-on;
		regulator-boot-on;
	};

	/* Generic mainline SBU mux for the Type-C connector's AUX/DP path. */
	usb_c_sbu_mux: usb-c-sbu-mux {
		compatible = "gpio-sbu-mux";
		enable-gpios = <&tlmm 183 GPIO_ACTIVE_LOW>;
		select-gpios = <&tlmm 180 GPIO_ACTIVE_HIGH>;
		mode-switch;
		orientation-switch;

		port {
			usb_c_sbu_mux_in: endpoint {
				remote-endpoint = <&sm5714_sbu_out>;
			};
		};
	};
};

&pm8550vs_d {
	status = "okay";
};

&pm8550vs_d_gpios {
	eusb2_reset_default: eusb2-reset-state {
		pins = "gpio4";
		function = "normal";
		power-source = <1>;
		input-enable;
		output-enable;
		drive-push-pull;
		qcom,drive-strength = <PMIC_GPIO_STRENGTH_MED>;
		bias-disable;
	};
};

&tlmm {
	/* CS35L45 shared reset (gpio42) + interrupt (gpio14) lines, all four amps. */
	cs35l45_gpio_default: cs35l45-gpio-default-state {
		pins = "gpio14", "gpio42";
		function = "gpio";
		drive-strength = <2>;
		bias-disable;
	};

	/*
	 * S Pen (Wacom WEZ01 EMR digitizer) interrupt + pen-in-garage detect
	 * (gts9wifi-fedora pivot). Presence confirmed on this exact X716B
	 * unit: `scripts/extract-vendor-firmware.sh` pulled a real
	 * `wez01_gts9.bin` from /vendor/firmware/keyboard_stm -- the "gts9"
	 * suffix (not "gts9wifi" or a model-specific one) suggesting this
	 * firmware/IC is shared across the whole Tab S9 family, not X710-
	 * specific. The driver itself never loads this blob at runtime (the
	 * IC runs factory-flashed firmware -- see kernel/drivers/
	 * touchscreen-wacom-wez01-x716.c's header), so its presence is only
	 * useful here as confirmation the digitizer hardware itself exists.
	 */
	epen_int_default: epen-int-default-state {
		pins = "gpio154";
		function = "gpio";
		drive-strength = <2>;
		input-enable;
		bias-disable;
	};

	epen_pdct_default: epen-pdct-default-state {
		pins = "gpio137";
		function = "gpio";
		drive-strength = <2>;
		input-enable;
		bias-disable;
	};

	/* PRIMARY_MI2S TDM lines to the four CS35L45 amplifiers. */
	tdm0_clk_active: tdm0-clk-active-state {
		pins = "gpio126";
		function = "i2s0_sck";
		drive-strength = <2>;
		bias-disable;
		output-high;
	};

	tdm0_ws_active: tdm0-ws-active-state {
		pins = "gpio129";
		function = "i2s0_ws";
		drive-strength = <2>;
		bias-disable;
		output-high;
	};

	tdm0_din_active: tdm0-din-active-state {
		pins = "gpio127";
		function = "i2s0_data0";
		drive-strength = <2>;
		bias-disable;
	};

	tdm0_dout_active: tdm0-dout-active-state {
		pins = "gpio128";
		function = "i2s0_data1";
		drive-strength = <2>;
		bias-disable;
	};

	sm5714_usbpd_int: sm5714-usbpd-int-state {
		pins = "gpio133";
		function = "gpio";
		drive-strength = <8>;
		input-enable;
		bias-disable;
	};

	sm5714_otg_det_default: sm5714-otg-det-default-state {
		pins = "gpio89";
		function = "gpio";
		drive-strength = <2>;
		output-low;
		bias-disable;
	};

	sm5714_vbus_dischg_default: sm5714-vbus-dischg-default-state {
		pins = "gpio175";
		function = "gpio";
		drive-strength = <2>;
		output-low;
		bias-pull-down;
	};

	/*
	 * Panel tear-effect (TE) line routed to the MDP vsync input. gpio86
	 * is measured, not guessed: X716's own stock DTS decodes the same
	 * panel node's qcom,platform-te-gpio as 0x56 = 86
	 * (gts9_eur_openx_w00_r00.dts:8498), and this is independently the
	 * exact GPIO ubuntu-galaxy-tab-s9ultra's sibling board also uses for
	 * the same purpose (kernel/dts/sm8550-samsung-gts9uwifi.dts:1092-1097)
	 * -- two independent sources agreeing on the same platform pin.
	 */
	sde_te: sde-te-state {
		pins = "gpio86";
		function = "mdp_vsync";
		drive-strength = <2>;
		bias-pull-down;
	};
};

&gpi_dma1 {
	status = "okay";
};

&gpi_dma2 {
	status = "okay";
};

/*
 * QUP wrapper nodes -- the actual root cause of "zero i2c adapters ever
 * appear" (found 2026-09-05 via a fork investigation after CONFIG_I2C_QCOM_GENI=y
 * alone didn't fix it): i2c6/i2c12/i2c_hub_8/i2c_hub_9 below are children
 * of these three "qcom,geni-se-qup"/"qcom,geni-se-i2c-master-hub" wrapper
 * nodes in sm8550.dtsi, which own the shared AHB/QUPV3 clock and resource
 * setup every child serial engine sits on top of. All three default to
 * `status = "disabled"` in the SoC dtsi -- enabling only the child i2c
 * nodes (as this file did until now) is a no-op if of_platform_populate()
 * never even creates a platform device for their parent. This explains
 * why all four buses failed completely identically: one missing override,
 * not four separate bus-level or regulator-level problems.
 */
&qupv3_id_0 {
	status = "okay";
};

&qupv3_id_1 {
	status = "okay";
};

&i2c_master_hub_0 {
	status = "okay";
};

/*
 * Touchscreen: STMicroelectronics fts1ba90a at 0x49, decoded from X716's
 * own stock DTS (gts9_eur_openx_w00_r04.dts, matching this tablet's
 * measured board-id 04 -- docs/hardware-facts.md). GPI-DMA prerequisite
 * (&gpi_dma1 above) is already satisfied by the earlier QUP-wrapper fix.
 * See kernel/drivers/touchscreen-fts1ba90a-x716.c for the driver and its
 * own citations, and docs/porting-log.md for why this needed a from-scratch
 * driver port rather than just this DTS node.
 *
 * Re-enabled in Session 7 after Session 6's crash was root-caused to a
 * wrong AVDD voltage value, not a TrustZone restriction -- see the
 * vreg_l14b_3p2 node comment above (&apps_rsc's regulators-0 block) and
 * docs/porting-log.md's Session 7 entry for the full investigation.
 */
&i2c4 {
	clock-frequency = <400000>;
	status = "okay";

	touchscreen@49 {
		compatible = "stm,fts_touch";
		reg = <0x49>;
		interrupts-extended = <&tlmm 25 IRQ_TYPE_LEVEL_LOW>;
		vddio-supply = <&vreg_l12b_1p8>;
		avdd-supply = <&vreg_l14b_3p2>;
		/*
		 * touchscreen-size-x/y: 1600/2560, from `sec,max_coords`
		 * in THIS board's own stock DTS
		 * (gts9_eur_openx_w00_r04.dts, matching this tablet's
		 * measured board-id 04) -- verified to equal the ANA38407
		 * panel's own native pixel resolution exactly
		 * (qcom,mdss-dsi-panel-width/height = 2560/1600), i.e. zero
		 * border/margin between raw touch units and panel pixels.
		 * Session 7 first used 1752/2800 here -- the r00
		 * (pre-production, still wired to the Tab S8+'s "gts8p"
		 * touch firmware/calibration) board revision's value, not
		 * r04's -- which produced a consistent ~3/4cm real-hardware
		 * touch offset. Fixed and confirmed correct on real hardware.
		 * See docs/porting-log.md's Session 7 entry.
		 */
		touchscreen-size-x = <1600>;
		touchscreen-size-y = <2560>;
		/*
		 * The sensor's native axes don't match the panel's mounted
		 * orientation: confirmed on real hardware (Session 7) by
		 * tapping the on-screen top-left and bottom-right corners and
		 * capturing raw ABS_MT_POSITION_X/Y events (top-left ->
		 * raw ~(1535, 50); bottom-right -> raw ~(55, 2505)). The raw
		 * Y axis's ~2455 span vs. raw X's ~1480 span (ratio ~1.66)
		 * matches the panel's own 2560x1600 aspect ratio (1.6),
		 * confirming a swap; working through
		 * touchscreen_parse_properties()'s exact transform order
		 * (invert pre-swap, then swap) against both measured corners
		 * gives this combination -- swap plus inverting only the
		 * pre-swap X axis -- as the one that maps both corners
		 * correctly. See docs/porting-log.md's Session 7 entry.
		 */
		touchscreen-swapped-x-y;
		touchscreen-inverted-x;
	};
};

/*
 * S Pen digitizer, I2C3 (gts9wifi-fedora pivot). GPI-DMA-only bus on
 * SM8550 like i2c4/i2c6/i2c12 -- &gpi_dma1 above already covers it.
 */
&i2c3 {
	clock-frequency = <400000>;
	status = "okay";

	digitizer@56 {
		compatible = "wacom,w90xx";
		reg = <0x56>;
		interrupts-extended = <&tlmm 154 IRQ_TYPE_LEVEL_LOW>;
		/* shared with the panel VCI rail */
		avdd-supply = <&vreg_l13b_3p0>;
		/* fw-mode enable: must stay low for normal operation */
		flash-mode-gpios = <&tlmm 179 GPIO_ACTIVE_HIGH>;
		/* pen-in-garage detect (high = pen holstered) */
		pdct-gpios = <&tlmm 137 GPIO_ACTIVE_HIGH>;
		pinctrl-names = "default";
		pinctrl-0 = <&epen_int_default>, <&epen_pdct_default>;
		/*
		 * The digitizer's raw axes don't match the panel's mounted
		 * orientation either, same as the touchscreen@49 node above.
		 * Confirmed algebraically (not just guessed) from this
		 * driver's own queried limits (docs/porting-log.md:
		 * `max_x 14752, max_y 23603`, i.e. 147.52mm x 236.03mm at
		 * this driver's fixed 100 units/mm) against the panel's real
		 * physical size (docs/hardware-facts.md: 236mm x 148mm
		 * landscape/native) -- raw X spans the panel's short (148mm)
		 * dimension and raw Y spans the long (236mm) one, so X/Y are
		 * swapped relative to native. Reported symptom on real
		 * hardware: the pen tracked correctly only with GNOME's
		 * rotation manually set to one specific non-native state and
		 * stayed "stuck" in that geometry through every other
		 * rotation -- exactly what an unswapped raw frame plus (see
		 * the accompanying libwacom fix, docs/porting-log.md) no
		 * automatic per-rotation calibration would produce.
		 *
		 * Starting from the touchscreen's own confirmed combination
		 * (swap plus inverting only the pre-swap X axis) as the most
		 * likely match, since both sensors sit on the same panel --
		 * to be confirmed/corrected via the same real-hardware
		 * corner-tap method Session 7 used, see docs/porting-log.md.
		 */
		touchscreen-swapped-x-y;
		touchscreen-inverted-x;
	};
};

&i2c6 {
	clock-frequency = <400000>;
	status = "okay";

	eusb2_repeater: redriver@4f {
		compatible = "nxp,ptn3222";
		reg = <0x4f>;
		#phy-cells = <0>;

		vdd3v3-supply = <&vreg_l5b_3p104>;
		vdd1v8-supply = <&vreg_l15b_1p8>;
		reset-gpios = <&pm8550vs_d_gpios 4 GPIO_ACTIVE_LOW>;
		/*
		 * Corrected 2026-09-07 (gts9wifi-fedora pivot): our sequence was
		 * missing the (0x03, 0x09) pair gts9wifi-fedora's real, working
		 * DTS carries for this identical chip (nxp,ptn3222) at the same
		 * i2c address on the same eUSB2-repeater role -- this is the
		 * exact override sequence Phase 2's eUSB2-PHY-init patch expects
		 * to be complete, and is a real, direct value fix rather than a
		 * cross-SKU guess (the register/value pairing itself, unlike
		 * e.g. GPIO numbers, isn't board-wiring-dependent -- it's the
		 * chip's own init sequence).
		 */
		qcom,param-override-seq = <0x20 0x06 0x21 0x07
					   0x63 0x08 0x03 0x09
					   0x01 0x0a>;

		pinctrl-names = "default";
		pinctrl-0 = <&eusb2_reset_default>;
	};
};

&i2c12 {
	clock-frequency = <400000>;
	status = "okay";

	ps5169: redriver@28 {
		compatible = "parade,ps5169";
		reg = <0x28>;
		parade,reg50 = <0x10>;
		parade,reg51 = <0x70>;
		parade,reg54 = <0x02>;
		parade,reg5d = <0x40>;
		usb-role-switch = <&usb_1>;
		retimer-switch;
		orientation-switch;

		ports {
			#address-cells = <1>;
			#size-cells = <0>;

			port@0 {
				reg = <0>;

				ps5169_ss_out: endpoint {
					remote-endpoint = <&sm5714_ss_in>;
				};
			};

			port@1 {
				reg = <1>;

				ps5169_ss_in: endpoint {
					remote-endpoint =
						<&usb_dp_qmpphy_out>;
				};
			};
		};
	};
};

&i2c_hub_8 {
	clock-frequency = <400000>;
	status = "okay";

	sm5714_charger: charger@49 {
		compatible = "siliconmitus,sm5714";
		reg = <0x49>;
		monitored-battery = <&battery>;
	};
};

&i2c_hub_9 {
	clock-frequency = <400000>;
	status = "okay";

	sm5714_usbpd: usbpd@33 {
		compatible = "siliconmitus,sm5714-usbpd";
		reg = <0x33>;
		interrupts-extended = <&tlmm 133 IRQ_TYPE_LEVEL_LOW>;
		pinctrl-names = "default";
		pinctrl-0 = <&sm5714_usbpd_int &sm5714_otg_det_default
			     &sm5714_vbus_dischg_default>;
		otg-det-gpios = <&tlmm 89 GPIO_ACTIVE_HIGH>;
		wakeup-source;

		sm5714_connector: connector {
			compatible = "usb-c-connector";
			power-role = "dual";
			data-role = "dual";
			try-power-role = "sink";
			displayport = <&mdss_dp0>;

			/*
			 * Samsung limits the switching-charger PD path to 15 W and
			 * 9 V; PPS direct charging through sm5440_direct (below)
			 * raises the programmable APDO once its own Q4 path opens.
			 */
			op-sink-microwatt = <15000000>;
			sink-pdos = <PDO_FIXED(5000, 3000,
					       PDO_FIXED_DUAL_ROLE |
					       PDO_FIXED_DATA_SWAP |
					       PDO_FIXED_USB_COMM)
				     PDO_FIXED(9000, 1660,
					       PDO_FIXED_USB_COMM)>;
			source-pdos = <PDO_FIXED(5000, 900,
						 PDO_FIXED_DUAL_ROLE |
						 PDO_FIXED_DATA_SWAP |
						 PDO_FIXED_USB_COMM)>;

			/*
			 * Re-added 2026-09-07 (gts9wifi-fedora pivot): the CONFIG_DRM=m
			 * concern that justified dropping this in Session 4 no longer
			 * applies -- CONFIG_DRM is built in for this port (needed for
			 * the panel/GPU work landed since), so CONFIG_TYPEC_DP_ALTMODE
			 * can be too. Matches gts9wifi-fedora's real, working altmode
			 * registration verbatim (same svid/vdo values -- these come
			 * from the Type-C DisplayPort alt-mode spec itself, not
			 * board-specific wiring, so no cross-SKU caveat applies here).
			 * Properties must precede subnodes in DTC -- this block has
			 * to come after sink-pdos/source-pdos above and before the
			 * `ports` subnode below.
			 */
			altmodes {
				displayport {
					svid = /bits/ 16 <0xff01>;
					vdo = <0x00001c46>;
				};
			};

			ports {
				#address-cells = <1>;
				#size-cells = <0>;

				port@0 {
					reg = <0>;

					sm5714_hs_in: endpoint {
						remote-endpoint =
							<&usb_1_dwc3_hs>;
					};
				};

				port@1 {
					reg = <1>;

					sm5714_ss_in: endpoint {
						remote-endpoint =
							<&ps5169_ss_out>;
					};
				};

				port@2 {
					reg = <2>;

					sm5714_sbu_out: endpoint {
						remote-endpoint =
							<&usb_c_sbu_mux_in>;
					};
				};
			};
		};
	};
};

/*
 * Speaker I2C bus (gts9wifi-fedora pivot). Samsung numbers this I2C18;
 * mainline is SE6 of the dedicated QUPv3 I2C master hub (already enabled
 * above), where all four CS35L45 amplifiers live.
 *
 * 400 kHz, not the 1 MHz the downstream stack uses: their real port found
 * that under mainline the QUPv3 i2c-master-hub runs its SEs in FIFO/PIO
 * mode (no GPI DMA), and at 1 MHz Fast-Mode Plus the SE accepts the M_CMD
 * but never drives the bus. Every upstream SM8550 board that puts real
 * devices on this hub runs it at <=400 kHz; 400 kHz is ample for CS35L45
 * register access and DSP firmware download.
 */
&i2c_hub_6 {
	clock-frequency = <400000>;
	status = "okay";

	cs35l45_rl: amplifier@30 {
		compatible = "cirrus,cs35l45";
		reg = <0x30>;
		#sound-dai-cells = <1>;
		interrupt-parent = <&tlmm>;
		interrupts = <14 IRQ_TYPE_LEVEL_LOW>;
		reset-gpios = <&tlmm 42 GPIO_ACTIVE_HIGH>;
		vdd-a-supply = <&speaker_vdd>;
		vdd-batt-supply = <&speaker_vdd>;
		pinctrl-names = "default";
		pinctrl-0 = <&cs35l45_gpio_default>;
		sound-name-prefix = "Rear Left";
		cirrus,asp-sdout-hiz-ctrl = <3>;

		cirrus,gpio-ctrl1 {
			gpio-ctrl = <2>;
		};

		cirrus,gpio-ctrl2 {
			gpio-ctrl = <2>;
		};
	};

	cs35l45_fl: amplifier@31 {
		compatible = "cirrus,cs35l45";
		reg = <0x31>;
		#sound-dai-cells = <1>;
		interrupt-parent = <&tlmm>;
		interrupts = <14 IRQ_TYPE_LEVEL_LOW>;
		reset-gpios = <&tlmm 42 GPIO_ACTIVE_HIGH>;
		vdd-a-supply = <&speaker_vdd>;
		vdd-batt-supply = <&speaker_vdd>;
		pinctrl-names = "default";
		pinctrl-0 = <&cs35l45_gpio_default>;
		sound-name-prefix = "Front Left";
		cirrus,asp-sdout-hiz-ctrl = <3>;

		cirrus,gpio-ctrl1 {
			gpio-ctrl = <2>;
		};

		cirrus,gpio-ctrl2 {
			gpio-ctrl = <2>;
		};
	};

	cs35l45_rr: amplifier@32 {
		compatible = "cirrus,cs35l45";
		reg = <0x32>;
		#sound-dai-cells = <1>;
		interrupt-parent = <&tlmm>;
		interrupts = <14 IRQ_TYPE_LEVEL_LOW>;
		reset-gpios = <&tlmm 42 GPIO_ACTIVE_HIGH>;
		vdd-a-supply = <&speaker_vdd>;
		vdd-batt-supply = <&speaker_vdd>;
		pinctrl-names = "default";
		pinctrl-0 = <&cs35l45_gpio_default>;
		sound-name-prefix = "Rear Right";
		cirrus,asp-sdout-hiz-ctrl = <3>;

		cirrus,gpio-ctrl1 {
			gpio-ctrl = <2>;
		};

		cirrus,gpio-ctrl2 {
			gpio-ctrl = <2>;
		};
	};

	cs35l45_fr: amplifier@33 {
		compatible = "cirrus,cs35l45";
		reg = <0x33>;
		#sound-dai-cells = <1>;
		interrupt-parent = <&tlmm>;
		interrupts = <14 IRQ_TYPE_LEVEL_LOW>;
		reset-gpios = <&tlmm 42 GPIO_ACTIVE_HIGH>;
		vdd-a-supply = <&speaker_vdd>;
		vdd-batt-supply = <&speaker_vdd>;
		pinctrl-names = "default";
		pinctrl-0 = <&cs35l45_gpio_default>;
		sound-name-prefix = "Front Right";
		cirrus,asp-sdout-hiz-ctrl = <3>;

		cirrus,gpio-ctrl1 {
			gpio-ctrl = <2>;
		};

		cirrus,gpio-ctrl2 {
			gpio-ctrl = <2>;
		};
	};
};

/*
 * FM+ drive-strength fix (gts9wifi-fedora pivot). Their real port traced
 * "Timeout waiting for OTP boot" on this exact bus/chip combination to
 * mainline's generic hub_i2c6_data_clk state asking for the weakest TLMM
 * setting (drive-strength = <2>), which cannot meet FM+ timing against
 * four amplifier loads -- the GENI controller never completes the first
 * transfer. Samsung's own qupv3_hub_i2c6_{sda,scl}_active states use <8>
 * for the same two pins; match that (hub_i2c6_data_clk is SoC-level,
 * defined in sm8550.dtsi itself, same as hub_i2c4_data_clk above).
 */
&hub_i2c6_data_clk {
	drive-strength = <8>;
};

&usb_1_hsphy {
	vdd-supply = <&vreg_l1e_0p88>;
	vdda12-supply = <&vreg_l3e_1p2>;
	phys = <&eusb2_repeater>;
	status = "okay";
};

&usb_1 {
	/*
	 * dr_mode = "peripheral" added 2026-09-05 after a deep investigation
	 * traced ps5169/sm5714-usbpd's stalled probe to dwc3 itself: without
	 * an explicit dr_mode, dwc3_get_dr_mode() (drivers/usb/dwc3/core.c)
	 * does a *live hardware readback* of GHWPARAMS0 to decide DRD vs
	 * peripheral-only, and only calls dwc3_setup_role_switch() (which
	 * registers the /sys/class/usb_role/ device ps5169's
	 * fwnode_usb_role_switch_get() call blocks on, forever, once
	 * fw_devlink/deferred_probe_timeout stopped masking it) when that
	 * readback resolves to OTG. If the silicon reports peripheral-only
	 * capability, that registration is permanently skipped -- not a
	 * timing issue, an architectural one. Since the actual goal here is
	 * only a plain USB2 gadget serial console (not Type-C role
	 * negotiation, PD, or DisplayPort alt mode), forcing peripheral mode
	 * explicitly removes the dependency on that hardware-readback path
	 * entirely, rather than continuing to chase whether it would have
	 * resolved to OTG on its own. ps5169 (SuperSpeed/DP redriver) and
	 * sm5714-usbpd (TCPM/PD) are expected to remain unbound after this --
	 * both are for functionality outside this port's actual goal, and
	 * ptn3222 (already bound, confirmed) handles the USB2 HS signal path
	 * a plain gadget serial console actually needs.
	 *
	 * DELIBERATELY NOT REMOVED YET (gts9wifi-fedora pivot): their own
	 * real, working DTS has no dr_mode override on &usb_1 at all, and
	 * gets full USB host mode + Type-C PD + docks working on this exact
	 * SM8550 dwc3 IP block -- proof the "peripheral-only" GHWPARAMS0
	 * readback found above isn't a silicon limitation, since it's the
	 * identical controller. But that finding came from a real, live
	 * hardware readback on *this* unit at a time when the eUSB2 PHY init
	 * sequence and TCPM role-retention fixes (Phase 2's `match-samsung-
	 * sm8550-eusb2-phy-init.patch`, `configure-nxp-ptn3222-from-dt.patch`,
	 * the two `tcpm-*-retained-*.patch` patches) weren't applied yet --
	 * removing this override before those land risks reproducing the
	 * exact regression this fix solved (the only working debug console
	 * failing outright), not fixing anything. Remove `dr_mode` and
	 * re-test only once those patches are in place, as one deliberate,
	 * isolated change -- not bundled with anything else, matching this
	 * project's own single-variable-change discipline throughout.
	 */
	dr_mode = "peripheral";
	status = "okay";
};

&usb_1_dwc3_hs {
	remote-endpoint = <&sm5714_hs_in>;
};

&usb_dp_qmpphy {
	vdda-phy-supply = <&vreg_l3e_1p2>;
	vdda-pll-supply = <&vreg_l3f_0p88>;
	status = "okay";
};

&usb_dp_qmpphy_out {
	remote-endpoint = <&ps5169_ss_in>;
};

/*
 * DisplayPort altmode over USB-C (gts9wifi-fedora pivot). Their real,
 * working DTS carries this exact quirk for the same ANA38407 panel this
 * file already drives: qcom,defer-hpd-until-first-resume works around a
 * cold-boot ordering issue where activating the external DPU encoder
 * before the panel's first platform suspend/resume cycle resets the
 * board. Ported verbatim -- this is a DPU/encoder-sequencing fact tied to
 * the panel part itself, not board-specific wiring.
 */
&mdss_dp0 {
	qcom,defer-hpd-until-first-resume;
	status = "okay";
};

/*
 * Native display pipeline: Samsung/Anapass ANA38407 DDIC, part AMSA10FA01
 * (2560x1600, DSC 1.1, 2 slices 1280x100, 8bpp -- measured, see
 * kernel/drivers/panel-samsung-ana38407-x716.c's header). Added Session 5,
 * 2026-09-05. mdss/mdss_dsi0/mdss_dsi0_phy/dispcc nodes are already fully
 * defined in sm8550.dtsi, just status = "disabled" by default -- structure
 * here mirrors ubuntu-galaxy-tab-s9ultra's own working display bring-up
 * for the same SoC generation/DDIC family
 * (kernel/dts/sm8550-samsung-gts9uwifi.dts:746-749,1801-1840) as closely as
 * possible, with X716-specific reset-gpio/te-gpio/resolution/DSC values
 * substituted in. See docs/porting-log.md's Session 5 entry for the full
 * rationale and confidence notes on each individual property below --
 * this subtree carries more unverified guesses than any other part of
 * this board file (no mainline driver or DTS precedent exists for this
 * exact panel part anywhere), and is expected to need real-hardware
 * iteration to get right, the same way USB bring-up did.
 */
&dispcc {
	status = "okay";
};

&mdss {
	status = "okay";
};

&mdss_dsi0 {
	vdda-supply = <&vreg_l3e_1p2>;
	status = "okay";

	panel@0 {
		compatible = "samsung,ana38407-amsa10fa01";
		reg = <0>;

		vddio-supply = <&vreg_l12b_1p8>;
		vdd-supply = <&vreg_l11b_1p2>;
		vci-supply = <&vreg_l13b_3p0>;
		avdd-supply = <&display_avdd>;

		/*
		 * reset-gpios/te-gpios: both cross-confirmed from X716's own
		 * stock DTS (qcom,platform-reset-gpio = 0x7d = 125,
		 * qcom,platform-te-gpio = 0x56 = 86;
		 * gts9_eur_openx_w00_r00.dts:8497-8498), and independently
		 * matching the exact same GPIO numbers
		 * ubuntu-galaxy-tab-s9ultra's sibling board uses for its own
		 * (different-part) ANA38407-family panel -- high confidence.
		 */
		reset-gpios = <&tlmm 125 GPIO_ACTIVE_HIGH>;
		te-gpios = <&tlmm 86 GPIO_ACTIVE_HIGH>;

		pinctrl-0 = <&sde_te>;
		pinctrl-names = "default";

		port {
			panel0_in: endpoint {
				remote-endpoint = <&mdss_dsi0_out>;
			};
		};
	};
};

&mdss_dsi0_out {
	data-lanes = <0 1 2 3>;
	remote-endpoint = <&panel0_in>;
};

&mdss_dsi0_phy {
	vdds-supply = <&vreg_l1e_0p88>;
	status = "okay";
};

/*
 * WiFi/BT: Qualcomm QCA6490 combo chip (Networking bring-up session).
 * Measured directly from this device's own stock DTS
 * (gts9_eur_openx_w00_r04.dts, board-id 04): fragment@143 ("bt_qca6490",
 * compatible "qcom,qca6490") and fragment@147 ("qcom,cnss-qca6490") --
 * corrects an earlier wrong assumption of WCN7850 (the sibling X910
 * Ultra's chip, a different chip family entirely; see
 * docs/hardware-facts.md and docs/porting-log.md). WiFi is ath11k over
 * PCIe0; mainline's ath11k has no separate QCA6490 PCI-ID or
 * devicetree-compatible entry at all -- it's treated as software-
 * identical to QCA6390 (compatible "pci17cb,1101"), confirmed directly in
 * Documentation/devicetree/bindings/net/wireless/qcom,ath11k-pci.yaml.
 * Bluetooth is hci_qca/btqca over UART14, compatible "qcom,wcn6855-bt"
 * (corrected from an earlier "qcom,qca6390-bt" guess -- Networking
 * bring-up session, full-fix boot test: real hardware readback over
 * UART14 showed "QCA ROM Version: 0x00000201" i.e. rom_ver 0x21, and
 * this device's real /vendor/firmware only ships "hp"-prefixed rom_ver-21
 * BT patch/NVM files (hpbtfw21.tlv, hpnv21*.bin/.b9a/.baa/...) -- no
 * "ht"-prefixed file exists anywhere on-device or in upstream
 * linux-firmware. drivers/bluetooth/btqca.c's QCA_QCA6390 case requests
 * "htbtfw/htnv" with NO fallback, but QCA_WCN6855's case tries
 * "wcnhpbtfw"/"wcnhpnv" first and explicitly falls back to plain
 * "hpbtfw"/"hpnv" on failure -- landing exactly on this device's real
 * files. Safe to switch soc_type this way: hci_qca's qca_soc_data_wcn6855
 * carries its own 6-entry vregs list, but qca_serdev_probe() only ever
 * consults it when the BT node has an "enable-gpios" property (ours
 * doesn't -- power is centrally handled by the wcn_pmu pwrseq device
 * below), so it takes the devm_pwrseq_get() path regardless of soc_type,
 * identically to before. See docs/porting-log.md's Networking bring-up
 * Session 8 entry.
 *
 * GPIO80 (WLAN_EN), GPIO81 (BT_EN), GPIO82 (SW_CTRL/coex), GPIO204
 * (XO_CLK): measured directly from the stock DTS's fragment@143/@147 and
 * its __fixups__ table. Regulator rails (L15B/S4E/S6G/S4G/S2G): also
 * measured from the same source. Mapping those downstream property names
 * onto mainline's differently-named vdd*-supply properties below is a
 * best-effort semantic match (pointing each mainline property at
 * whichever physical rail the downstream node ties the *equivalent*
 * property to) -- NOT yet independently confirmed on real hardware. If
 * WiFi/BT probe fails with a regulator error, re-check this mapping
 * first; see docs/porting-log.md's Networking bring-up session entry.
 *
 * &uart14 is a completely different QUP instance (SE14, 0x898000) from
 * this board's own &uart7/serial0 debug console (SE7, 0xa9c000) -- no
 * conflict, resolved by fragment adjacency in the stock DTS (bt_qca6490
 * is fragment@143; the very next fragment, @144, enables
 * qupv3_se14_4uart specifically). Confirmed the sibling X910 Ultra port
 * uses this exact same physical UART instance for its own (different
 * chip's) Bluetooth.
 */
&pcie0 {
	/*
	 * perst-gpios/wake-gpios (94/96): this board's own stock DTS does
	 * NOT override these at all (no perst/wake property anywhere in
	 * its &pcie0 fragment, fragment@125 -- only qcom,target-link-speed
	 * and qcom,no-l0s-supported). 94/96 is inherited by analogy from
	 * two convergent sources instead: the sibling X910 Ultra port's own
	 * board (same numbers, kernel/dts/sm8550-samsung-gts9uwifi.dts:1693-1699)
	 * and Documentation/devicetree/bindings/pci/qcom,pcie-sm8550.yaml's
	 * own worked example (same numbers again) -- likely the common
	 * SM8550 QRD reference design pinout this board's own overlay never
	 * needed to override. Re-verify if PCIe never links up.
	 */
	perst-gpios = <&tlmm 94 GPIO_ACTIVE_LOW>;
	wake-gpios = <&tlmm 96 GPIO_ACTIVE_HIGH>;
	pinctrl-names = "default";
	pinctrl-0 = <&pcie0_default_state>;
	status = "okay";
};

&pcie0_phy {
	/*
	 * Reused from this board's own already-proven UFS-PHY and USB-PHY
	 * rail assignments (&ufs_mem_phy, &usb_1_hsphy above) -- common
	 * PHY-shared rails on this SoC, not separately confirmed for PCIe
	 * specifically, but a reasonable analogy given the pattern already
	 * holds across two other PHYs on this exact board.
	 */
	vdda-phy-supply = <&vreg_l1e_0p88>;
	vdda-pll-supply = <&vreg_l3e_1p2>;
	status = "okay";
};

/*
 * QCA6390 PMU power sequencer (Documentation/devicetree/bindings/
 * regulator/qcom,qca6390-pmu.yaml). Discovered live on real hardware
 * (Networking bring-up session): wifi@0/bluetooth's own regulator
 * properties are NOT board-PMIC rails directly -- this project's first
 * attempt wired them that way and the PCIe host controller sat in
 * permanent EPROBE_DEFER as a result. The correct architecture is three
 * layers: this board's real PMIC rails feed *this* pmu node's own
 * vdd*-supply input properties; the pmu node exposes its own internal
 * "regulators { ldo0..ldo9 }" outputs; wifi@0/bluetooth (below) consume
 * *those* outputs, not the raw board rails. wlan-enable-gpios(80)/
 * bt-enable-gpios(81) live on this node too -- this is what actually
 * powers on the physical combo chip (missing entirely from the first
 * attempt, which only wired 80/81 into unused pinctrl states with no
 * real consumer).
 *
 * Input-rail mapping (board rails -> pmu inputs) is a best-effort
 * semantic match, same caveat as before: downstream's own property names
 * (qcom,bt-vdd-... and vdd-wlan-...) don't line up 1:1 with this binding's
 * input names, and downstream itself uses different physical rails for
 * WLAN's vs BT's own "aon" concept (S2G vs S4E) where mainline's PMU node
 * expects a single, shared vddaon-supply for the whole combo chip.
 *
 * CORRECTED 2026-09-06 (Networking bring-up session, agent research round
 * 3): the first attempt guessed S4E for vddaon-supply (BT's own naming
 * looked more directly analogous to "AON"). Independent evidence from this
 * board's own stock DTS __fixups__ table says otherwise: S2G is WLAN's
 * *only* AON-labeled rail (vdd-wlan-aon-supply) and is also the chip's
 * open-loop-CPR-controlled rail (qcom,vreg_ol_cpr = "s2g") -- both are
 * hallmarks of a true dedicated AON supply. S4E, by contrast, feeds BT's
 * aon/dig/rfa0p8 AND WLAN's *digital* (not AON) input -- a shared
 * "always-on-adjacent" rail, not the chip's real AON rail. Swapped:
 * vddaon-supply is now S2G, vddpmu-supply is now S4E. Still not
 * independently confirmed on real hardware -- if WLAN/BT never power on,
 * re-check this mapping first; see docs/porting-log.md's Networking
 * bring-up session entry.
 */
/ {
	wcn_pmu: wcn-pmu {
		compatible = "qcom,qca6390-pmu";

		/*
		 * AOP QMP mailbox PDC resource votes, measured verbatim from
		 * this board's own stock DTS's qcom,cnss-qca6490 node
		 * (gts9_eur_openx_w00_r04.dts:15355 -- the fuller of its two
		 * near-identical WLAN/BT copies of this table). Consumed by
		 * kernel/patches/qca6390-pwrseq-cold-reset-aop.patch's
		 * pwrseq_qcom_wcn_program_wlan_pdc(); required in addition to
		 * the unpark-pcie0-pipe-mux.patch PHY fix -- confirmed live on
		 * real hardware that the PHY fix alone left "Device not
		 * found" unresolved. See docs/porting-log.md's Networking
		 * bring-up session entry.
		 */
		qcom,qmp = <&aoss_qmp>;
		qcom,wlan-pdc-init =
			"{class: wlan_pdc, ss: rf, res: s4e.v, upval: 966}",
			"{class: wlan_pdc, ss: rf, res: s4e.v, dwnval: 615}",
			"{class: wlan_pdc, ss: rf, res: s4g.v, upval: 1350}",
			"{class: wlan_pdc, ss: rf, res: s4g.v, dwnval: 945}",
			"{class: wlan_pdc, ss: rf, res: s6g.v, upval: 1900}",
			"{class: wlan_pdc, ss: rf, res: s6g.v, dwnval: 1825}",
			"{class: wlan_pdc, ss: rf, res: s2g.m, enable: 1}",
			"{class: wlan_pdc, ss: rf, res: s2g.v, enable: 1}",
			"{class: wlan_pdc, ss: rf, res: s2g.v, upval: 1012}",
			"{class: wlan_pdc, ss: rf, res: s2g.v, dwnval: 800}",
			"{class: wlan_pdc, ss: bb, res: pdc, enable: 0}";

		wlan-enable-gpios = <&tlmm 80 GPIO_ACTIVE_HIGH>;
		bt-enable-gpios = <&tlmm 81 GPIO_ACTIVE_HIGH>;
		/*
		 * XO-clock-enable GPIO 204, matching this board's own stock DTS
		 * (qcom,xo-clk-gpio on both the qcom,cnss-qca6490 WLAN node and
		 * the BT node). Consumed by kernel/patches/qca6490-xo-clk-gpio.patch,
		 * which wires pwrseq-qcom-wcn.c's existing (but previously
		 * WCN6855-only) xo-clk-gpio assert/deassert sequencing into the
		 * QCA6390/QCA6490 pdata table. A prior single-variable bisection
		 * pass wrongly suspected this property of causing wcn-pmu's probe
		 * to regress to permanent -EPROBE_DEFER; the real cause (root-
		 * caused via drivers/regulator/qcom-rpmh-regulator.c's real RPMH
		 * voltage-step table) was the S4G/S6G regulator voltages being
		 * set to off-grid values in that same round of changes, not this
		 * GPIO. See docs/porting-log.md's Networking bring-up session
		 * entry.
		 */
		xo-clk-gpios = <&tlmm 204 GPIO_ACTIVE_HIGH>;

		vddaon-supply = <&vreg_s2g_0p98>;
		vddpmu-supply = <&vreg_s4e_0p952>;
		vddrfa0p95-supply = <&vreg_s4e_0p952>;
		vddrfa1p3-supply = <&vreg_s4g_1p352>;
		vddrfa1p9-supply = <&vreg_s6g_1p904>;
		vddpcie1p3-supply = <&vreg_s4g_1p352>;
		vddpcie1p9-supply = <&vreg_s6g_1p904>;
		vddio-supply = <&vreg_l15b_1p8>;

		regulators {
			vreg_pmu_rfa_cmn: ldo0 {
				regulator-name = "vreg_pmu_rfa_cmn";
			};

			vreg_pmu_aon_0p59: ldo1 {
				regulator-name = "vreg_pmu_aon_0p59";
			};

			vreg_pmu_wlcx_0p8: ldo2 {
				regulator-name = "vreg_pmu_wlcx_0p8";
			};

			vreg_pmu_wlmx_0p85: ldo3 {
				regulator-name = "vreg_pmu_wlmx_0p85";
			};

			vreg_pmu_btcmx_0p85: ldo4 {
				regulator-name = "vreg_pmu_btcmx_0p85";
			};

			vreg_pmu_rfa_0p8: ldo5 {
				regulator-name = "vreg_pmu_rfa_0p8";
			};

			vreg_pmu_rfa_1p2: ldo6 {
				regulator-name = "vreg_pmu_rfa_1p2";
			};

			vreg_pmu_rfa_1p7: ldo7 {
				regulator-name = "vreg_pmu_rfa_1p7";
			};

			vreg_pmu_pcie_0p9: ldo8 {
				regulator-name = "vreg_pmu_pcie_0p9";
			};

			vreg_pmu_pcie_1p8: ldo9 {
				regulator-name = "vreg_pmu_pcie_1p8";
			};
		};
	};
};

&pcieport0 {
	wifi@0 {
		compatible = "pci17cb,1101"; /* QCA6390 ID -- see header comment above */
		reg = <0x10000 0x0 0x0 0x0 0x0>;
		vddrfacmn-supply = <&vreg_pmu_rfa_cmn>;
		vddaon-supply = <&vreg_pmu_aon_0p59>;
		vddwlcx-supply = <&vreg_pmu_wlcx_0p8>;
		vddwlmx-supply = <&vreg_pmu_wlmx_0p85>;
		vddrfa0p8-supply = <&vreg_pmu_rfa_0p8>;
		vddrfa1p2-supply = <&vreg_pmu_rfa_1p2>;
		vddrfa1p7-supply = <&vreg_pmu_rfa_1p7>;
		vddpcie0p9-supply = <&vreg_pmu_pcie_0p9>;
		vddpcie1p8-supply = <&vreg_pmu_pcie_1p8>;
	};
};

/*
 * 32 MiB WLAN DMA carveout, matching this board's own stock DTS exactly
 * (gts9_eur_openx_w00_r04.dts fragment@146, cnss_wlan_region) --
 * shared-dma-pool, no fixed address needed (CMA-allocated).
 */
&reserved_memory {
	cnss_wlan_region: cnss-wlan-region {
		compatible = "shared-dma-pool";
		alloc-ranges = <0x0 0x0 0x0 0xffffffff>;
		reusable;
		alignment = <0x0 0x400000>;
		size = <0x0 0x2000000>;
	};
};

&uart14 {
	status = "okay";

	bluetooth {
		compatible = "qcom,wcn6855-bt";
		vddrfacmn-supply = <&vreg_pmu_rfa_cmn>;
		vddaon-supply = <&vreg_pmu_aon_0p59>;
		vddbtcmx-supply = <&vreg_pmu_btcmx_0p85>;
		vddrfa0p8-supply = <&vreg_pmu_rfa_0p8>;
		vddrfa1p2-supply = <&vreg_pmu_rfa_1p2>;
		vddrfa1p7-supply = <&vreg_pmu_rfa_1p7>;
		max-speed = <3200000>;

		/*
		 * Root-caused via direct kernel source reading (Networking
		 * bring-up session): with no BD_ADDR at all, this chip's
		 * real hardware has no persistent storage of its own
		 * factory Bluetooth address (Samsung's stock system reads
		 * it from its own EFS partition at runtime -- not yet
		 * extracted here, and not something mainline's hci_qca/
		 * btqca even looks for). Per
		 * net/bluetooth/hci_sync.c's own hci_power_on(): an
		 * all-zero/absent BD_ADDR makes hci_dev_get_bd_addr_from_property()
		 * find nothing, so `invalid_bdaddr` stays true, which sets
		 * HCI_UNCONFIGURED -- and mgmt.c's read_index_list()
		 * explicitly excludes any HCI_UNCONFIGURED device, which is
		 * exactly why hci0 probed and loaded real firmware
		 * (confirmed in dmesg) yet BlueZ/bluetoothctl reported "No
		 * default controller available" with kernel mgmt itself
		 * reporting "Number of controllers: 0". This is the same
		 * "factory NVM MAC address is null, needs an EFS-read
		 * fixup" gotcha the sibling X910 Ultra port's own bring-up
		 * already flagged as a known risk for this chip family.
		 *
		 * `local-bd-address` here is a locally-administered
		 * placeholder, NOT this device's real factory address --
		 * bytes are stored LSB-first (confirmed:
		 * net/bluetooth/hci_sync.c reads this straight into
		 * `bdaddr_t.b[6]`, and displays as b[5]:b[4]:...:b[0]), so
		 * this `[1A 2B 3C 4D 5E 02]` array displays as
		 * `02:5E:4D:3C:2B:1A` -- the 0x02 first-octet gives the
		 * standard "locally administered" bit (see
		 * Documentation/devicetree/bindings/net/bluetooth/brcm,bcm4377-bluetooth.yaml's
		 * own example for the same convention), avoiding collision
		 * with any real vendor-assigned OUI. The real address would
		 * need extracting from the stock system's own EFS
		 * partition, not yet done. Good enough to make BT fully
		 * usable (visible, pairable) for bring-up; revisit with the
		 * real address if this device's own persistent BT identity
		 * (e.g. surviving a reflash, matching what a paired peer
		 * remembers) ever matters. See docs/porting-log.md's
		 * Networking bring-up session entry.
		 */
		local-bd-address = [1A 2B 3C 4D 5E 02];
	};
};

/*
 * Adreno 740 GPU (gts9wifi-fedora pivot, Session 9). gpucc/the GMU/the
 * adreno SMMU are all already enabled by default in sm8550.dtsi -- only
 * the &gpu node itself ships `status = "disabled"`, gated because the
 * zap shader must be signed for this device's TrustZone and no generic
 * unsigned firmware exists.
 *
 * Confirmed directly against gts9wifi-fedora's own real-hardware-proven
 * DTS (same SoC, same GPU, sibling tablet in the same family): this is
 * the *entire* override needed -- `status = "okay"` plus a zap-shader
 * firmware-name pointing at Samsung's own signed MDT. Not guessed: this
 * device's own real `a740_zap.mdt` + `a740_zap.b00/b01/b02` (the split
 * MDT+blob PIL image format) and `gmu_gen70200.bin` (the GMU's own
 * firmware, needs no DT override -- the a6xx_gmu driver resolves its
 * default firmware name from the GMU's own compatible string) are
 * already extracted from this exact device's own /vendor/firmware into
 * vendor-firmware-dump/firmware/ (via scripts/extract-vendor-
 * firmware.sh, Networking bring-up session) -- these need staging into
 * the eventual rootfs's /lib/firmware/qcom/ (and /lib/firmware/qcom/ for
 * gmu_gen70200.bin) before this will actually probe successfully, not
 * yet done as of this DTS change. See docs/porting-log.md's
 * gts9wifi-fedora pivot entry.
 */
&gpu {
	status = "okay";

	zap-shader {
		firmware-name = "qcom/a740_zap.mdt";
	};
};

/*
 * ADSP (audio DSP / SSC sensors), gts9wifi-fedora pivot. Adopted directly
 * from their real DTS, all three parts independently confirmed necessary
 * against our own pinned mainline v7.2 tree (not board-specific facts --
 * genuine SoC/mainline-tree gaps, so equally applicable here):
 *
 * - `firmware-name` needs BOTH entries: mainline's `sm8550-adsp-pas`
 *   driver has `dtb_pas_id` set (confirmed: `memory-region = <&adspslpi_mem>,
 *   <&q6_adsp_dtb_mem>;` in sm8550.dtsi's own remoteproc_adsp node), so the
 *   second firmware-name entry is mandatory -- without it
 *   request_firmware() for the DTB half fails and the ADSP never boots.
 *   Samsung's own signed `adsp.mdt`/`adsp_dtb.mdt` (extracted from this
 *   device's own `apnhlos` partition, same TWRP-based method as the GPU/
 *   WiFi/BT firmware already pulled this project) are used because
 *   Samsung's secure boot rejects the generic Qualcomm-signed
 *   `qcom/sm8550/adsp.mbn` reference blob.
 * - `/delete-property/ interconnects`: confirmed directly against our own
 *   pinned sm8550.dtsi (`kernel/linux/arch/arm64/boot/dts/qcom/sm8550.dtsi`)
 *   that the default `interconnects = <&lpass_lpicx_noc ...>` path never
 *   resolves on this mainline tree's registered icc graph (the LPASS
 *   sub-graph doesn't connect to `mc_virt`) -- this permanently
 *   `EPROBE_DEFER`s the ADSP otherwise. `qcom_q6v5_init()` treats a NULL
 *   interconnects path as valid (a no-op `icc_set_bw()`), so deleting the
 *   property lets PAS auth/boot actually proceed. A genuine mainline-tree
 *   gap, not a board-specific fix -- revisit if the LPASS interconnect
 *   graph is ever fixed upstream.
 * - `pinctrl-0 = <&hub_i2c4_data_clk>`: also SoC-level, not board-specific
 *   (defined in sm8550.dtsi itself, confirmed) -- SSC needs sensor-hub
 *   SE3/SE4 muxed; gts9wifi-fedora's own comment notes SE3 is already
 *   claimed by their SM5440 charge-pump in GPI-DMA mode on their board,
 *   so only SE4's state is listed here. X716B's own SE3/SE4 usage is not
 *   yet independently re-verified -- if ADSP probe fails with a pinctrl
 *   conflict ("pin ... already requested by ..."), check this first.
 */
&remoteproc_adsp {
	firmware-name = "qcom/sm8550/adsp.mdt",
			"qcom/sm8550/adsp_dtb.mdt";
	pinctrl-names = "default";
	pinctrl-0 = <&hub_i2c4_data_clk>;
	/delete-property/ interconnects;
	status = "okay";
};

/*
 * PPS direct-charge pump (gts9wifi-fedora pivot). QUP hub SE3 is the
 * dedicated bus for the SM5440 2:1 charge pump at 0x63. Their real port
 * found this is also an SSC-visible hub: enabling the upstream controller
 * in its default FIFO/PIO mode resets the SE and makes the complete SSC
 * sensor registry disappear -- Samsung drives this exact node through GPI
 * DMA instead, so match that topology (GPI TREs, not AP-side PIO
 * reprogramming of the shared serial engine). The SM5440 driver
 * coordinates with the sm5714_usbpd TCPM path above and requests PPS
 * through Linux TCPM once the sink advertises a programmable APDO.
 */
&i2c_hub_3 {
	clock-frequency = <400000>;
	dmas = <&gpi_dma1 0 3 QCOM_GPI_I2C>,
	       <&gpi_dma1 1 3 QCOM_GPI_I2C>;
	dma-names = "tx", "rx";
	qcom,enable-gsi-dma;
	status = "okay";

	sm5440_direct: charger@63 {
		compatible = "siliconmitus,sm5440";
		reg = <0x63>;
		tcpm-power-supply = <&sm5714_usbpd>;
	};
};

/*
 * Battery thermistor (gts9wifi-fedora pivot). Samsung's battery safety
 * input is the external pack thermistor, not the SM5714 fuel-gauge die
 * temperature. Their real DTS exposes it as PMK8550 ADC5 Gen3 virtual
 * channel 0x144 (PM8550 SID 1, AMUX1 with 100 kOhm pull-up) -- wired into
 * sm5714_charger below as its battery-temp io-channel.
 */
&pmk8550 {
	pmk8550_vadc: adc@9000 {
		compatible = "qcom,spmi-adc5-gen3";
		reg = <0x9000>, <0x9100>;
		interrupts = <0x0 0x90 0x1 IRQ_TYPE_EDGE_RISING>,
			     <0x0 0x91 0x1 IRQ_TYPE_EDGE_RISING>;
		#address-cells = <1>;
		#size-cells = <0>;
		#io-channel-cells = <1>;
		#thermal-sensor-cells = <1>;

		channel@144 {
			reg = <0x144>;
			label = "battery-thermistor";
			qcom,pre-scaling = <1 1>;
			qcom,ratiometric;
			qcom,hw-settle-time = <200>;
			qcom,avg-samples = <4>;
		};
	};
};

&sm5714_charger {
	io-channels = <&pmk8550_vadc 0x144>;
	io-channel-names = "battery-temp";
};

/*
 * Speakers (gts9wifi-fedora pivot). The X710/X716 family has no WSA884x
 * speaker path and no WCD938x -- its four CS35L45 amplifiers (wired above
 * on &i2c_hub_6) consume PRIMARY_MI2S_RX over the TDM lines on
 * TLMM126..129 (also wired above). Keep the first card deliberately
 * small, matching their real, working config: one playback backend plus
 * the native VA-macro DMIC capture backend.
 */
&lpass_tlmm {
	dmic45_default: dmic45-default-state {
		clk-pins {
			pins = "gpio12";
			function = "dmic3_clk";
			drive-strength = <8>;
			output-high;
		};

		data-pins {
			pins = "gpio13";
			function = "dmic3_data";
			drive-strength = <8>;
			input-enable;
		};
	};

	dmic67_default: dmic67-default-state {
		clk-pins {
			pins = "gpio17";
			function = "dmic4_clk";
			drive-strength = <8>;
			output-high;
		};

		data-pins {
			pins = "gpio18";
			function = "dmic4_data";
			drive-strength = <8>;
			input-enable;
		};
	};
};

&lpass_vamacro {
	pinctrl-names = "default";
	pinctrl-0 = <&dmic01_default>, <&dmic23_default>,
		    <&dmic45_default>, <&dmic67_default>;
	/*
	 * Without this the driver logs "qcom,dmic-sample-rate dt entry
	 * missing" and never derives the DMIC clock divider, so the
	 * decimators run with no clock and capture returns pure silence.
	 * 4.8 MHz is what every other mainline board with VA-macro DMICs
	 * uses and divides cleanly out of the VA macro's 19.2 MHz mclk.
	 */
	qcom,dmic-sample-rate = <4800000>;
	vdd-micb-supply = <&vreg_l10b_1p8>;
	status = "okay";
};

/*
 * LPASS interconnect providers disabled (gts9wifi-fedora pivot). Ported
 * directly from their real, working DTS. Their own comment there frames
 * this as a v0.5/"milestone 1" bring-up shortcut ("audio out of scope"),
 * which reads as stale given their README lists speakers as working -- but
 * the override itself is still live in their real, shipped DTS today, so
 * it is what their actually-working config depends on regardless of the
 * comment's own claim. remoteproc_adsp's own interconnects property is
 * already deleted above, and the sound card's DAI links don't route
 * through these providers, so disabling them costs nothing reachable from
 * this port's audio path.
 */
&lpass_ag_noc {
	status = "disabled";
};

&lpass_lpiaon_noc {
	status = "disabled";
};

&lpass_lpicx_noc {
	status = "disabled";
};

/ {
	sound {
		compatible = "qcom,sm8550-sndcard", "qcom,sm8450-sndcard";
		model = "Samsung-Galaxy-Tab-S9-5G";
		pinctrl-names = "default";
		pinctrl-0 = <&tdm0_clk_active>, <&tdm0_ws_active>,
			    <&tdm0_din_active>, <&tdm0_dout_active>;

		speaker-playback-dai-link {
			link-name = "CS35L45 Speaker Playback";

			cpu {
				sound-dai = <&q6apmbedai PRIMARY_MI2S_RX>;
			};

			codec {
				sound-dai = <&cs35l45_fl 0>, <&cs35l45_fr 0>,
					    <&cs35l45_rl 0>, <&cs35l45_rr 0>;
			};

			platform {
				sound-dai = <&q6apm>;
			};
		};

		va-capture-dai-link {
			link-name = "Internal DMIC Capture";

			cpu {
				/*
				 * The VA macro has its own LPASS DMA lane:
				 * capture lands on VA_CODEC_DMA_TX_0, not on
				 * the TX macro's TX_CODEC_DMA_TX_3 (where the
				 * reference boards take soundwire mics from,
				 * which this tablet does not have). Wiring the
				 * link to the TX lane leaves the backend with
				 * no data and arecord fails with -EIO.
				 */
				sound-dai = <&q6apmbedai VA_CODEC_DMA_TX_0>;
			};

			codec {
				sound-dai = <&lpass_vamacro 0>;
			};

			platform {
				sound-dai = <&q6apm>;
			};
		};
	};
};
